AUTOSAR XML (schema 4-2-2)
package /STELLANTIS/EPT/ASWCs
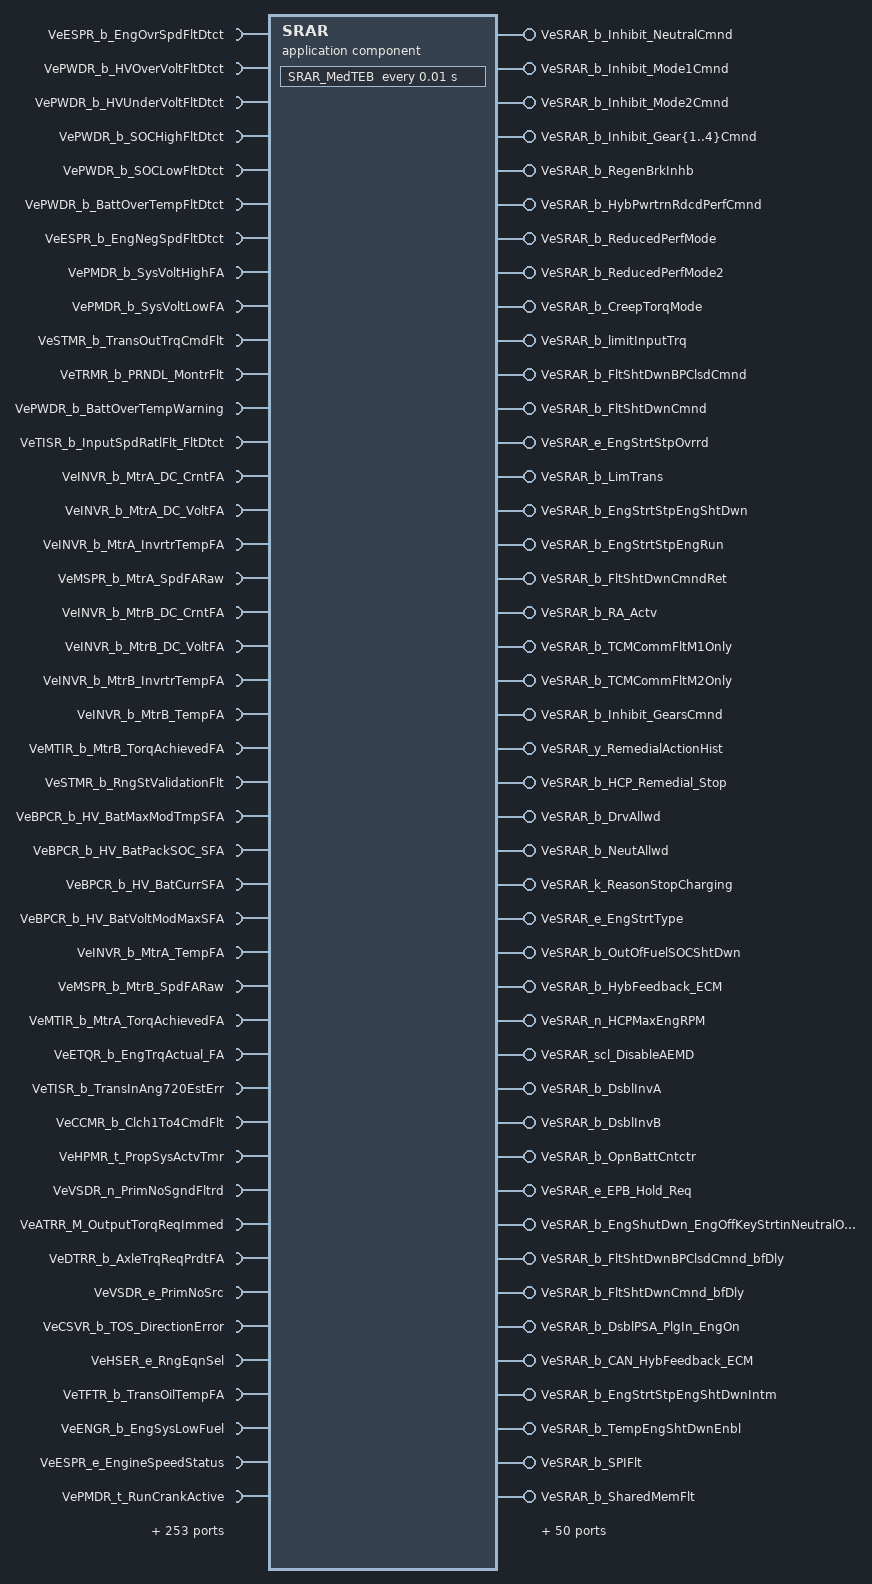
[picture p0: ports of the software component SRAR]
  application sw component type SRAR
    296 x require port:
      VeESPR_b_EngOvrSpdFltDtct: nonqueued-receiver-com-spec{data-element=Value, init-value=0}, required-interface=VeESPR_b_EngOvrSpdFltDtct
      VePWDR_b_HVOverVoltFltDtct: nonqueued-receiver-com-spec{data-element=Value, init-value=0}, required-interface=VePWDR_b_HVOverVoltFltDtct
      VePWDR_b_HVUnderVoltFltDtct: nonqueued-receiver-com-spec{data-element=Value, init-value=0}, required-interface=VePWDR_b_HVUnderVoltFltDtct
      VePWDR_b_SOCHighFltDtct: nonqueued-receiver-com-spec{data-element=Value, init-value=0}, required-interface=VePWDR_b_SOCHighFltDtct
      VePWDR_b_SOCLowFltDtct: nonqueued-receiver-com-spec{data-element=Value, init-value=0}, required-interface=VePWDR_b_SOCLowFltDtct
      VePWDR_b_BattOverTempFltDtct: nonqueued-receiver-com-spec{data-element=Value, init-value=0}, required-interface=VePWDR_b_BattOverTempFltDtct
      VeESPR_b_EngNegSpdFltDtct: nonqueued-receiver-com-spec{data-element=Value, init-value=0}, required-interface=VeESPR_b_EngNegSpdFltDtct
      VePMDR_b_SysVoltHighFA: nonqueued-receiver-com-spec{data-element=Value, init-value=0}, required-interface=VePMDR_b_SysVoltHighFA
      VePMDR_b_SysVoltLowFA: nonqueued-receiver-com-spec{data-element=Value, init-value=0}, required-interface=VePMDR_b_SysVoltLowFA
      VeSTMR_b_TransOutTrqCmdFlt: nonqueued-receiver-com-spec{data-element=Value, init-value=0}, required-interface=VeSTMR_b_TransOutTrqCmdFlt
      VeTRMR_b_PRNDL_MontrFlt: nonqueued-receiver-com-spec{data-element=Value, init-value=0}, required-interface=VeTRMR_b_PRNDL_MontrFlt
      VePWDR_b_BattOverTempWarning: nonqueued-receiver-com-spec{data-element=Value, init-value=0}, required-interface=VePWDR_b_BattOverTempWarning
      VeTISR_b_InputSpdRatlFlt_FltDtct: nonqueued-receiver-com-spec{data-element=Value, init-value=0}, required-interface=VeTISR_b_InputSpdRatlFlt_FltDtct
      VeINVR_b_MtrA_DC_CrntFA: nonqueued-receiver-com-spec{data-element=Value, init-value=0}, required-interface=VeINVR_b_MtrA_DC_CrntFA
      VeINVR_b_MtrA_DC_VoltFA: nonqueued-receiver-com-spec{data-element=Value, init-value=0}, required-interface=VeINVR_b_MtrA_DC_VoltFA
      VeINVR_b_MtrA_InvrtrTempFA: nonqueued-receiver-com-spec{data-element=Value, init-value=0}, required-interface=VeINVR_b_MtrA_InvrtrTempFA
      VeMSPR_b_MtrA_SpdFARaw: nonqueued-receiver-com-spec{data-element=Value, init-value=0}, required-interface=VeMSPR_b_MtrA_SpdFARaw
      VeINVR_b_MtrB_DC_CrntFA: nonqueued-receiver-com-spec{data-element=Value, init-value=0}, required-interface=VeINVR_b_MtrB_DC_CrntFA
      VeINVR_b_MtrB_DC_VoltFA: nonqueued-receiver-com-spec{data-element=Value, init-value=0}, required-interface=VeINVR_b_MtrB_DC_VoltFA
      VeINVR_b_MtrB_InvrtrTempFA: nonqueued-receiver-com-spec{data-element=Value, init-value=0}, required-interface=VeINVR_b_MtrB_InvrtrTempFA
      VeINVR_b_MtrB_TempFA: nonqueued-receiver-com-spec{data-element=Value, init-value=0}, required-interface=VeINVR_b_MtrB_TempFA
      VeMTIR_b_MtrB_TorqAchievedFA: nonqueued-receiver-com-spec{data-element=Value, init-value=0}, required-interface=VeMTIR_b_MtrB_TorqAchievedFA
      VeSTMR_b_RngStValidationFlt: nonqueued-receiver-com-spec{data-element=Value, init-value=0}, required-interface=VeSTMR_b_RngStValidationFlt
      VeBPCR_b_HV_BatMaxModTmpSFA: nonqueued-receiver-com-spec{data-element=Value, init-value=0}, required-interface=VeBPCR_b_HV_BatMaxModTmpSFA
      VeBPCR_b_HV_BatPackSOC_SFA: nonqueued-receiver-com-spec{data-element=Value, init-value=0}, required-interface=VeBPCR_b_HV_BatPackSOC_SFA
      VeBPCR_b_HV_BatCurrSFA: nonqueued-receiver-com-spec{data-element=Value, init-value=0}, required-interface=VeBPCR_b_HV_BatCurrSFA
      VeBPCR_b_HV_BatVoltModMaxSFA: nonqueued-receiver-com-spec{data-element=Value, init-value=0}, required-interface=VeBPCR_b_HV_BatVoltModMaxSFA
      VeINVR_b_MtrA_TempFA: nonqueued-receiver-com-spec{data-element=Value, init-value=0}, required-interface=VeINVR_b_MtrA_TempFA
      VeMSPR_b_MtrB_SpdFARaw: nonqueued-receiver-com-spec{data-element=Value, init-value=0}, required-interface=VeMSPR_b_MtrB_SpdFARaw
      VeMTIR_b_MtrA_TorqAchievedFA: nonqueued-receiver-com-spec{data-element=Value, init-value=0}, required-interface=VeMTIR_b_MtrA_TorqAchievedFA
      VeETQR_b_EngTrqActual_FA: nonqueued-receiver-com-spec{data-element=Value, init-value=0}, required-interface=VeETQR_b_EngTrqActual_FA
      VeTISR_b_TransInAng720EstErr: nonqueued-receiver-com-spec{data-element=Value, init-value=0}, required-interface=VeTISR_b_TransInAng720EstErr
      VeCCMR_b_Clch1To4CmdFlt: nonqueued-receiver-com-spec{data-element=Value, init-value=0}, required-interface=VeCCMR_b_Clch1To4CmdFlt
      VeHPMR_t_PropSysActvTmr: nonqueued-receiver-com-spec{data-element=Value, init-value=0}, required-interface=VeHPMR_t_PropSysActvTmr
      VeVSDR_n_PrimNoSgndFltrd: nonqueued-receiver-com-spec{data-element=Value, init-value=0}, required-interface=VeVSDR_n_PrimNoSgndFltrd
      VeATRR_M_OutputTorqReqImmed: nonqueued-receiver-com-spec{data-element=Value, init-value=0}, required-interface=VeATRR_M_OutputTorqReqImmed
      VeDTRR_b_AxleTrqReqPrdtFA: nonqueued-receiver-com-spec{data-element=Value, init-value=0}, required-interface=VeDTRR_b_AxleTrqReqPrdtFA
      VeVSDR_e_PrimNoSrc: nonqueued-receiver-com-spec{data-element=Value, init-value=CeVSDR_e_PrimNoSrcNotAvail}, required-interface=VeVSDR_e_PrimNoSrc
      VeCSVR_b_TOS_DirectionError: nonqueued-receiver-com-spec{data-element=Value, init-value=0}, required-interface=VeCSVR_b_TOS_DirectionError
      VeHSER_e_RngEqnSel: nonqueued-receiver-com-spec{data-element=Value, init-value=CeHSER_e_UseNeutralEqn}, required-interface=VeHSER_e_RngEqnSel
      VeTFTR_b_TransOilTempFA: nonqueued-receiver-com-spec{data-element=Value, init-value=0}, required-interface=VeTFTR_b_TransOilTempFA
      VeENGR_b_EngSysLowFuel: nonqueued-receiver-com-spec{data-element=Value, init-value=0}, required-interface=VeENGR_b_EngSysLowFuel
      VeESPR_e_EngineSpeedStatus: nonqueued-receiver-com-spec{data-element=Value, init-value=CeESPR_e_EngSpdNormal}, required-interface=VeESPR_e_EngineSpeedStatus
      VePMDR_t_RunCrankActive: nonqueued-receiver-com-spec{data-element=Value, init-value=0}, required-interface=VePMDR_t_RunCrankActive
      VeTIDR_b_EngTrqHVBattLoFA: nonqueued-receiver-com-spec{data-element=Value, init-value=0}, required-interface=VeTIDR_b_EngTrqHVBattLoFA
      VeTIDR_b_EngTrqHVBattHiFA: nonqueued-receiver-com-spec{data-element=Value, init-value=0}, required-interface=VeTIDR_b_EngTrqHVBattHiFA
      VeCSLR_n_Clch1_RawSlipSpeed: nonqueued-receiver-com-spec{data-element=Value, init-value=0}, required-interface=VeCSLR_n_Clch1_RawSlipSpeed
      VeCSLR_n_Clch2_RawSlipSpeed: nonqueued-receiver-com-spec{data-element=Value, init-value=0}, required-interface=VeCSLR_n_Clch2_RawSlipSpeed
      VeDFIR_b_PostCodeClrDiagDsbl: nonqueued-receiver-com-spec{data-element=Value, init-value=0}, required-interface=VeDFIR_b_PostCodeClrDiagDsbl
      VePMDR_e_PMM_PowerMode: nonqueued-receiver-com-spec{data-element=Value, init-value=CePMDR_e_PowerMode_Off}, required-interface=VePMDR_e_PMM_PowerMode
      VeSTRR_b_ImmedStop: nonqueued-receiver-com-spec{data-element=Value, init-value=0}, required-interface=VeSTRR_b_ImmedStop
      VeHPMR_b_MtrSystemActive: nonqueued-receiver-com-spec{data-element=Value, init-value=0}, required-interface=VeHPMR_b_MtrSystemActive
      VeTISR_n_InputSpeed: nonqueued-receiver-com-spec{data-element=Value, init-value=0}, required-interface=VeTISR_n_InputSpeed
      VeESSR_e_EngStrtStpMd: nonqueued-receiver-com-spec{data-element=Value, init-value=CeESSR_e_Stop}, required-interface=VeESSR_e_EngStrtStpMd
      VeBPCR_Pct_HV_BatPackSOC_Arb: nonqueued-receiver-com-spec{data-element=Value, init-value=0}, required-interface=VeBPCR_Pct_HV_BatPackSOC_Arb
      VeHPMR_b_PropSysActv: nonqueued-receiver-com-spec{data-element=Value, init-value=0}, required-interface=VeHPMR_b_PropSysActv
      VeENGR_b_EngOffRecom: nonqueued-receiver-com-spec{data-element=Value, init-value=0}, required-interface=VeENGR_b_EngOffRecom
      VeENGR_b_ZylAbs: nonqueued-receiver-com-spec{data-element=Value, init-value=0}, required-interface=VeENGR_b_ZylAbs
      VeETQR_M_EngTrqActual: nonqueued-receiver-com-spec{data-element=Value, init-value=0}, required-interface=VeETQR_M_EngTrqActual
      VeOHSR_e_RngDsrd: nonqueued-receiver-com-spec{data-element=Value, init-value=CeOHSR_e_RngSel_N}, required-interface=VeOHSR_e_RngDsrd
      VeHSER_e_RngSt: nonqueued-receiver-com-spec{data-element=Value, init-value=CeHSER_e_Init}, required-interface=VeHSER_e_RngSt
      VeTFTR_T_TransOilTemp: nonqueued-receiver-com-spec{data-element=Value, init-value=0}, required-interface=VeTFTR_T_TransOilTemp
      VeHCCR_e_SCA1_St: nonqueued-receiver-com-spec{data-element=Value, init-value=CeHCCR_e_SCA_Filling_Md}, required-interface=VeHCCR_e_SCA1_St
      VeHCCR_e_SCA2_St: nonqueued-receiver-com-spec{data-element=Value, init-value=CeHCCR_e_SCA_Filling_Md}, required-interface=VeHCCR_e_SCA2_St
      VeTHMR_e_ThrmSysShtDwnFlt: nonqueued-receiver-com-spec{data-element=Value, init-value=CeSRAR_e_NoFlt}, required-interface=VeTHMR_e_ThrmSysShtDwnFlt
      VeOBCR_e_ChrgSysShtDwnFlt: nonqueued-receiver-com-spec{data-element=Value, init-value=CeSRAR_e_NoFlt}, required-interface=VeOBCR_e_ChrgSysShtDwnFlt
      VeBTQR_b_RegenBrkAxleTrqReqFA: nonqueued-receiver-com-spec{data-element=Value, init-value=0}, required-interface=VeBTQR_b_RegenBrkAxleTrqReqFA
      VeBTQR_M_RegenBrkAxleTrqReq: nonqueued-receiver-com-spec{data-element=Value, init-value=0}, required-interface=VeBTQR_M_RegenBrkAxleTrqReq
      VeGENR_b_LowVoltSysFld: nonqueued-receiver-com-spec{data-element=Value, init-value=0}, required-interface=VeGENR_b_LowVoltSysFld
      VeGENR_U_IBS_BattVoltOut: nonqueued-receiver-com-spec{data-element=Value, init-value=0}, required-interface=VeGENR_U_IBS_BattVoltOut
      VeCSVR_v_VehSpd: nonqueued-receiver-com-spec{data-element=Value, init-value=0}, required-interface=VeCSVR_v_VehSpd
      VeESSR_b_AStrtFailed: nonqueued-receiver-com-spec{data-element=Value, init-value=0}, required-interface=VeESSR_b_AStrtFailed
      VeSTRR_e_HybStrtrSt: nonqueued-receiver-com-spec{data-element=Value, init-value=CeSTRR_e_KeyOffSt}, required-interface=VeSTRR_e_HybStrtrSt
      VeTRGR_e_VldtdTransRngSt: nonqueued-receiver-com-spec{data-element=Value, init-value=CeTRGR_e_NoSelectionAvailable}, required-interface=VeTRGR_e_VldtdTransRngSt
      VeBPCR_b_PwrLimON: nonqueued-receiver-com-spec{data-element=Value, init-value=0}, required-interface=VeBPCR_b_PwrLimON
      VeTISR_b_InputSpeedFA: nonqueued-receiver-com-spec{data-element=Value, init-value=0}, required-interface=VeTISR_b_InputSpeedFA
      VeESSR_e_EngStartStopSt: nonqueued-receiver-com-spec{data-element=Value, init-value=CeESSR_e_EngOff}, required-interface=VeESSR_e_EngStartStopSt
      VeOBCR_e_ChargingLevel: nonqueued-receiver-com-spec{data-element=Value, init-value=CeOBCR_e_ChargingLvlDefault}, required-interface=VeOBCR_e_ChargingLevel
      VePLTR_b_RmtVehStartReq: nonqueued-receiver-com-spec{data-element=Value, init-value=0}, required-interface=VePLTR_b_RmtVehStartReq
      VeSSDR_b_DrvAllwd: nonqueued-receiver-com-spec{data-element=Value, init-value=0}, required-interface=VeSSDR_b_DrvAllwd
      VeGSMR_b_PpawlInsrtMntrFailed: nonqueued-receiver-com-spec{data-element=Value, init-value=0}, required-interface=VeGSMR_b_PpawlInsrtMntrFailed
      VeTAPR_b_TransAuxPump_NotFlty: nonqueued-receiver-com-spec{data-element=Value, init-value=0}, required-interface=VeTAPR_b_TransAuxPump_NotFlty
      VeHCCR_V_UpperSump_Vol: nonqueued-receiver-com-spec{data-element=Value, init-value=0}, required-interface=VeHCCR_V_UpperSump_Vol
      VeCSDR_b_Clch1_Avail: nonqueued-receiver-com-spec{data-element=Value, init-value=0}, required-interface=VeCSDR_b_Clch1_Avail
      VeCSDR_b_Clch2_Avail: nonqueued-receiver-com-spec{data-element=Value, init-value=0}, required-interface=VeCSDR_b_Clch2_Avail
      VeTINR_b_Inhibit_Mode1: nonqueued-receiver-com-spec{data-element=Value, init-value=0}, required-interface=VeTINR_b_Inhibit_Mode1
      VeTINR_b_Inhibit_Mode2: nonqueued-receiver-com-spec{data-element=Value, init-value=0}, required-interface=VeTINR_b_Inhibit_Mode2
      VeTINR_b_Inhibit_Gear{1..4}: nonqueued-receiver-com-spec{data-element=Value, init-value=0}, required-interface=VeTINR_b_Inhibit_Gear{1..4}
      VeTINR_b_Inhibit_Neutral: nonqueued-receiver-com-spec{data-element=Value, init-value=0}, required-interface=VeTINR_b_Inhibit_Neutral
      VePWDR_e_HVOverVoltFailure: nonqueued-receiver-com-spec{data-element=Value, init-value=CeHVTR_e_HVOverVoltPass}, required-interface=VePWDR_e_HVOverVoltFailure
      VeMMMR_b_MtrMdVldtnFlt: nonqueued-receiver-com-spec{data-element=Value, init-value=0}, required-interface=VeMMMR_b_MtrMdVldtnFlt
      VeTITR_M_SnsdEng_Flt: nonqueued-receiver-com-spec{data-element=Value, init-value=0}, required-interface=VeTITR_M_SnsdEng_Flt
      VeTRGR_b_DisableDrvAllwd: nonqueued-receiver-com-spec{data-element=Value, init-value=0}, required-interface=VeTRGR_b_DisableDrvAllwd
      VeHPMR_e_PropSysMode: nonqueued-receiver-com-spec{data-element=Value, init-value=CeHPMR_e_Disabled}, required-interface=VeHPMR_e_PropSysMode
      VeTRGR_e_EPB_Hold_Req: nonqueued-receiver-com-spec{data-element=Value, init-value=CeTRGR_e_EPBReq_NA}, required-interface=VeTRGR_e_EPB_Hold_Req
      VeTINR_d_TCMFailures: nonqueued-receiver-com-spec{data-element=Value, init-value=0}, required-interface=VeTINR_d_TCMFailures
      VeTHMR_e_PPCTIS_OT: nonqueued-receiver-com-spec{data-element=Value, init-value=CeTHMR_e_EmergencyLevel4}, required-interface=VeTHMR_e_PPCTIS_OT
      VePMIR_e_LTPsvPumpDryRun: nonqueued-receiver-com-spec{data-element=Value, init-value=CePMPR_e_FTSNA_False}, required-interface=VePMIR_e_LTPsvPumpDryRun
      VeCPDR_b_LTPP_FunPer_FltDtct: nonqueued-receiver-com-spec{data-element=Value, init-value=0}, required-interface=VeCPDR_b_LTPP_FunPer_FltDtct
      VeESSR_g_StrtStpFailPhase: nonqueued-receiver-com-spec{data-element=Value, init-value=0}, required-interface=VeESSR_g_StrtStpFailPhase
      VeINVR_e_MtrA_InvrtrSt: nonqueued-receiver-com-spec{data-element=Value, init-value=CeINVR_e_NormalPowerStageOff}, required-interface=VeINVR_e_MtrA_InvrtrSt
      VeTTIR_b_TransTrqReqFst_Pass: nonqueued-receiver-com-spec{data-element=Value, init-value=0}, required-interface=VeTTIR_b_TransTrqReqFst_Pass
      VeENGR_b_ECM_Feedback_HCP: nonqueued-receiver-com-spec{data-element=Value, init-value=0}, required-interface=VeENGR_b_ECM_Feedback_HCP
      VeESSR_b_AStrtReattmptAllowed: nonqueued-receiver-com-spec{data-element=Value, init-value=0}, required-interface=VeESSR_b_AStrtReattmptAllowed
      VePLTR_b_InFieldMode: nonqueued-receiver-com-spec{data-element=Value, init-value=0}, required-interface=VePLTR_b_InFieldMode
      VePMDR_e_KeyStatus: nonqueued-receiver-com-spec{data-element=Value, init-value=CePMDR_e_KeySt_Off}, required-interface=VePMDR_e_KeyStatus
      VeOBCR_e_ChargingSystemSts: nonqueued-receiver-com-spec{data-element=Value, init-value=CeOBCR_e_NotCharging}, required-interface=VeOBCR_e_ChargingSystemSts
      VeTMIR_T_PsvPmpClnt_TmpIn: nonqueued-receiver-com-spec{data-element=Value, init-value=0}, required-interface=VeTMIR_T_PsvPmpClnt_TmpIn
      VeINVR_T_MtrB_InvrtrTemp: nonqueued-receiver-com-spec{data-element=Value, init-value=0}, required-interface=VeINVR_T_MtrB_InvrtrTemp
      VeINVR_T_MtrA_InvrtrTemp: nonqueued-receiver-com-spec{data-element=Value, init-value=0}, required-interface=VeINVR_T_MtrA_InvrtrTemp
      VeINVR_T_MtrB_Temp: nonqueued-receiver-com-spec{data-element=Value, init-value=0}, required-interface=VeINVR_T_MtrB_Temp
      VeINVR_T_MtrA_Temp: nonqueued-receiver-com-spec{data-element=Value, init-value=0}, required-interface=VeINVR_T_MtrA_Temp
      VeBPCR_b_HV_BatCntctrOpenPending: nonqueued-receiver-com-spec{data-element=Value, init-value=0}, required-interface=VeBPCR_b_HV_BatCntctrOpenPending
      VeINVR_b_MtrAFlt_HV_CntctrOpnRq: nonqueued-receiver-com-spec{data-element=Value, init-value=0}, required-interface=VeINVR_b_MtrAFlt_HV_CntctrOpnRq
      VeHSCR_n_Max_MtrA_Spd: nonqueued-receiver-com-spec{data-element=Value, init-value=0}, required-interface=VeHSCR_n_Max_MtrA_Spd
      VeINVR_b_MtrBFlt_HV_CntctrOpnRq: nonqueued-receiver-com-spec{data-element=Value, init-value=0}, required-interface=VeINVR_b_MtrBFlt_HV_CntctrOpnRq
      VeINVR_e_MtrB_InvrtrSt: nonqueued-receiver-com-spec{data-element=Value, init-value=CeINVR_e_NormalPowerStageOff}, required-interface=VeINVR_e_MtrB_InvrtrSt
      VeHSCR_n_Max_MtrB_Spd: nonqueued-receiver-com-spec{data-element=Value, init-value=0}, required-interface=VeHSCR_n_Max_MtrB_Spd
      VeTRNR_e_ActualGear: nonqueued-receiver-com-spec{data-element=Value, init-value=CeTRNR_e_Neutral}, required-interface=VeTRNR_e_ActualGear
      VeTRNR_e_TargetGear: nonqueued-receiver-com-spec{data-element=Value, init-value=CeTRNR_e_Neutral}, required-interface=VeTRNR_e_TargetGear
      VeTRNR_e_C1Stat: nonqueued-receiver-com-spec{data-element=Value, init-value=CeHCCR_e_ClInvalid}, required-interface=VeTRNR_e_C1Stat
      VeOSMR_n_TransMinEngSpd: nonqueued-receiver-com-spec{data-element=Value, init-value=0}, required-interface=VeOSMR_n_TransMinEngSpd
      VeENGR_e_ECMReqRemStop: nonqueued-receiver-com-spec{data-element=Value, init-value=CeENGR_e_Default}, required-interface=VeENGR_e_ECMReqRemStop
      VeBPCR_b_HV_BatCntctrOpenReq: nonqueued-receiver-com-spec{data-element=Value, init-value=0}, required-interface=VeBPCR_b_HV_BatCntctrOpenReq
      VeENGR_b_LV12PwrFreeRq: nonqueued-receiver-com-spec{data-element=Value, init-value=0}, required-interface=VeENGR_b_LV12PwrFreeRq
      VeENGR_b_EngTrq_Enbl_Rq_TCM: nonqueued-receiver-com-spec{data-element=Value, init-value=0}, required-interface=VeENGR_b_EngTrq_Enbl_Rq_TCM
      VeENGR_i_ECM_LHOM_Trans: nonqueued-receiver-com-spec{data-element=Value, init-value=0}, required-interface=VeENGR_i_ECM_LHOM_Trans
      VeCSLR_b_NC1_FA: nonqueued-receiver-com-spec{data-element=Value, init-value=0}, required-interface=VeCSLR_b_NC1_FA
      VeTINR_d_TCMLimphomeFaults: nonqueued-receiver-com-spec{data-element=Value, init-value=0}, required-interface=VeTINR_d_TCMLimphomeFaults
      VeTHMR_b_ThermalHybAltMode_Rq: nonqueued-receiver-com-spec{data-element=Value, init-value=0}, required-interface=VeTHMR_b_ThermalHybAltMode_Rq
      VeENGR_e_ComFailECM_C1CAN: nonqueued-receiver-com-spec{data-element=Value, init-value=CeENGR_e_NoFaultECM_C1}, required-interface=VeENGR_e_ComFailECM_C1CAN
      VeENGR_e_ComFailECM_ePtCAN: nonqueued-receiver-com-spec{data-element=Value, init-value=CeENGR_e_NoFaultECM_ePT}, required-interface=VeENGR_e_ComFailECM_ePtCAN
      VeTINR_e_ComFailTCM_C1CAN: nonqueued-receiver-com-spec{data-element=Value, init-value=CeTINR_e_NoFaultTCM_C1}, required-interface=VeTINR_e_ComFailTCM_C1CAN
      VeTINR_e_ComFailTCM_ePtCAN: nonqueued-receiver-com-spec{data-element=Value, init-value=CeTINR_e_NoFaultTCM_ePT}, required-interface=VeTINR_e_ComFailTCM_ePtCAN
      VeBRKR_e_ComFailBSM_C1CAN: nonqueued-receiver-com-spec{data-element=Value, init-value=CeBRKR_e_NoFaultBSM_C1}, required-interface=VeBRKR_e_ComFailBSM_C1CAN
      VeBRKR_e_ComFailBSM_C2CAN: nonqueued-receiver-com-spec{data-element=Value, init-value=CeBRKR_e_NoFaultBSM_C2}, required-interface=VeBRKR_e_ComFailBSM_C2CAN
      VeHTRR_b_Htr3Cntctr_StckClsdOvrTmp_Flg: nonqueued-receiver-com-spec{data-element=Value, init-value=0}, required-interface=VeHTRR_b_Htr3Cntctr_StckClsdOvrTmp_Flg
      VeIDCR_e_APM_FailureType: nonqueued-receiver-com-spec{data-element=Value, init-value=CeGENR_e_FailureType_NoFailure}, required-interface=VeIDCR_e_APM_FailureType
      VeBRKR_b_ABSActive: nonqueued-receiver-com-spec{data-element=Value, init-value=0}, required-interface=VeBRKR_b_ABSActive
      VeBRKR_b_ImpndSkid: nonqueued-receiver-com-spec{data-element=Value, init-value=0}, required-interface=VeBRKR_b_ImpndSkid
      VePMDR_b_SysVoltLowFA_BF1: nonqueued-receiver-com-spec{data-element=Value, init-value=0}, required-interface=VePMDR_b_SysVoltLowFA_BF1
      VePMDR_b_SysVoltLowFA_BF2: nonqueued-receiver-com-spec{data-element=Value, init-value=0}, required-interface=VePMDR_b_SysVoltLowFA_BF2
      VePMDR_b_SysVoltLowFA_HB: nonqueued-receiver-com-spec{data-element=Value, init-value=0}, required-interface=VePMDR_b_SysVoltLowFA_HB
      VeDMIR_e_DriveStyleSts: nonqueued-receiver-com-spec{data-element=Value, init-value=CeDMIR_e_Normal}, required-interface=VeDMIR_e_DriveStyleSts
      VeDTRR_b_OPDInhibit_HMI: nonqueued-receiver-com-spec{data-element=Value, init-value=0}, required-interface=VeDTRR_b_OPDInhibit_HMI
      VeAPSR_e_Lv1PVMode: nonqueued-receiver-com-spec{data-element=Value, init-value=CeAPSR_e_LV1PVMode_NotValid}, required-interface=VeAPSR_e_Lv1PVMode
      VeHSER_b_GRMActive: nonqueued-receiver-com-spec{data-element=Value, init-value=0}, required-interface=VeHSER_b_GRMActive
      VeSTRR_b_BumpStrtEngOn: nonqueued-receiver-com-spec{data-element=Value, init-value=0}, required-interface=VeSTRR_b_BumpStrtEngOn
      VeTINR_e_TransLimpRequest: nonqueued-receiver-com-spec{data-element=Value, init-value=CeTINR_e_LimpInactive}, required-interface=VeTINR_e_TransLimpRequest
      VeBPCR_b_ThrmlRnawyFlg: nonqueued-receiver-com-spec{data-element=Value, init-value=0}, required-interface=VeBPCR_b_ThrmlRnawyFlg
      VeSTRR_b_BumpStrtInhbt: nonqueued-receiver-com-spec{data-element=Value, init-value=0}, required-interface=VeSTRR_b_BumpStrtInhbt
      VeTRNR_e_C2Stat: nonqueued-receiver-com-spec{data-element=Value, init-value=CeHCCR_e_ClInvalid}, required-interface=VeTRNR_e_C2Stat
      VeDTRR_b_DrvrIntndedAxleTrqRawFA: nonqueued-receiver-com-spec{data-element=Value, init-value=0}, required-interface=VeDTRR_b_DrvrIntndedAxleTrqRawFA
      VeENGR_b_EngineStallDetected: nonqueued-receiver-com-spec{data-element=Value, init-value=0}, required-interface=VeENGR_b_EngineStallDetected
      VeCPDR_b_LTCL_FunPer_FltDtct: nonqueued-receiver-com-spec{data-element=Value, init-value=0}, required-interface=VeCPDR_b_LTCL_FunPer_FltDtct
      VeCPDR_b_LTCL_DryRun_FltDtct: nonqueued-receiver-com-spec{data-element=Value, init-value=0}, required-interface=VeCPDR_b_LTCL_DryRun_FltDtct
      VeBRKR_b_AeCoastReady: nonqueued-receiver-com-spec{data-element=Value, init-value=0}, required-interface=VeBRKR_b_AeCoastReady
      VeINVR_b_P1f_Dgrd_AltMd: nonqueued-receiver-com-spec{data-element=Value, init-value=0}, required-interface=VeINVR_b_P1f_Dgrd_AltMd
      VeTRNR_e_TCMActualEvenGear: nonqueued-receiver-com-spec{data-element=Value, init-value=CeTRNR_e_Neutral}, required-interface=VeTRNR_e_TCMActualEvenGear
      VeTINR_e_Synchro2Sts: nonqueued-receiver-com-spec{data-element=Value, init-value=CeHCCR_e_ClInvalid}, required-interface=VeTINR_e_Synchro2Sts
      VeTINR_e_Synchro1Sts: nonqueued-receiver-com-spec{data-element=Value, init-value=CeHCCR_e_ClInvalid}, required-interface=VeTINR_e_Synchro1Sts
      VeIMPR_b_HighVoltageRapidShtdwnCmnd: nonqueued-receiver-com-spec{data-element=Value, init-value=0}, required-interface=VeIMPR_b_HighVoltageRapidShtdwnCmnd
      VeBPCR_b_HVBatCntrWeld_ImpdOpn: nonqueued-receiver-com-spec{data-element=Value, init-value=0}, required-interface=VeBPCR_b_HVBatCntrWeld_ImpdOpn
      VeCSVR_b_CanSigVehSpd_FA: nonqueued-receiver-com-spec{data-element=Value, init-value=0}, required-interface=VeCSVR_b_CanSigVehSpd_FA
      VeCSVR_b_VehSpdVSOSigFailSts: nonqueued-receiver-com-spec{data-element=Value, init-value=0}, required-interface=VeCSVR_b_VehSpdVSOSigFailSts
      VePMDR_b_SysVoltLowFA_BF3: nonqueued-receiver-com-spec{data-element=Value, init-value=0}, required-interface=VePMDR_b_SysVoltLowFA_BF3
      VeMSPR_n_MtrB_Spd: nonqueued-receiver-com-spec{data-element=Value, init-value=0}, required-interface=VeMSPR_n_MtrB_Spd
      VeINVR_e_MtrC_InvrtrSt: nonqueued-receiver-com-spec{data-element=Value, init-value=CeINVR_e_NormalPowerStageOff}, required-interface=VeINVR_e_MtrC_InvrtrSt
      VeINVR_b_MtrCFlt_HV_CntctrOpnRq: nonqueued-receiver-com-spec{data-element=Value, init-value=0}, required-interface=VeINVR_b_MtrCFlt_HV_CntctrOpnRq
      VeINVR_e_MCPA_CommFail: nonqueued-receiver-com-spec{data-element=Value, init-value=CeSRAR_e_CommFail_NoFault}, required-interface=VeINVR_e_MCPA_CommFail
      VeINVR_e_MCPB_CommFail: nonqueued-receiver-com-spec{data-element=Value, init-value=CeSRAR_e_CommFail_NoFault}, required-interface=VeINVR_e_MCPB_CommFail
      VeINVR_b_MCPA_CommFailFA: nonqueued-receiver-com-spec{data-element=Value, init-value=0}, required-interface=VeINVR_b_MCPA_CommFailFA
      VeINVR_b_MCPB_CommFailFA: nonqueued-receiver-com-spec{data-element=Value, init-value=0}, required-interface=VeINVR_b_MCPB_CommFailFA
      VeBPCR_e_BPCM_CommFail: nonqueued-receiver-com-spec{data-element=Value, init-value=CeSRAR_e_CommFail_NoFault}, required-interface=VeBPCR_e_BPCM_CommFail
      VeBPCR_b_BPCM_CommFailFA: nonqueued-receiver-com-spec{data-element=Value, init-value=0}, required-interface=VeBPCR_b_BPCM_CommFailFA
      VeINVR_b_MtrBFlt_HV_CntctrOpnRq_FA: nonqueued-receiver-com-spec{data-element=Value, init-value=0}, required-interface=VeINVR_b_MtrBFlt_HV_CntctrOpnRq_FA
      VeBPCR_b_HVBatCntctrWeld_Qualifier: nonqueued-receiver-com-spec{data-element=Value, init-value=0}, required-interface=VeBPCR_b_HVBatCntctrWeld_Qualifier
      VeAPSR_b_AccelPedalEffPositionFA: nonqueued-receiver-com-spec{data-element=Value, init-value=0}, required-interface=VeAPSR_b_AccelPedalEffPositionFA
      VeADIR_b_LftWEDClosingFail: nonqueued-receiver-com-spec{data-element=Value, init-value=0}, required-interface=VeADIR_b_LftWEDClosingFail
      VeADIR_b_LftWEDOpeningFail: nonqueued-receiver-com-spec{data-element=Value, init-value=0}, required-interface=VeADIR_b_LftWEDOpeningFail
      VeADIR_b_RtWEDClosingFail: nonqueued-receiver-com-spec{data-element=Value, init-value=0}, required-interface=VeADIR_b_RtWEDClosingFail
      VeADIR_b_RtWEDOpeningFail: nonqueued-receiver-com-spec{data-element=Value, init-value=0}, required-interface=VeADIR_b_RtWEDOpeningFail
      VeDMAB_y_StatusByte_CM_AD_Perf: nonqueued-receiver-com-spec{data-element=Value, init-value=0}, required-interface=VeDMAB_y_StatusByte_CM_AD_Perf
      VeDMAB_y_StatusByte_CM_Chksum_Err: nonqueued-receiver-com-spec{data-element=Value, init-value=0}, required-interface=VeDMAB_y_StatusByte_CM_Chksum_Err
      VeDMAB_y_StatusByte_CM_LongTermMemReset: nonqueued-receiver-com-spec{data-element=Value, init-value=0}, required-interface=VeDMAB_y_StatusByte_CM_LongTermMemReset
      VeDMAB_y_StatusByte_CM_MainProc: nonqueued-receiver-com-spec{data-element=Value, init-value=0}, required-interface=VeDMAB_y_StatusByte_CM_MainProc
      VeDMAB_y_StatusByte_CM_OPDActivePerf: nonqueued-receiver-com-spec{data-element=Value, init-value=0}, required-interface=VeDMAB_y_StatusByte_CM_OPDActivePerf
      VeDMAB_y_StatusByte_CM_PLD: nonqueued-receiver-com-spec{data-element=Value, init-value=0}, required-interface=VeDMAB_y_StatusByte_CM_PLD
      VeDMAB_y_StatusByte_CM_ProcessorPerf: nonqueued-receiver-com-spec{data-element=Value, init-value=0}, required-interface=VeDMAB_y_StatusByte_CM_ProcessorPerf
      VeDMAB_y_StatusByte_CM_RAM_Err: nonqueued-receiver-com-spec{data-element=Value, init-value=0}, required-interface=VeDMAB_y_StatusByte_CM_RAM_Err
      VeDMAB_y_StatusByte_CM_ROM_Err: nonqueued-receiver-com-spec{data-element=Value, init-value=0}, required-interface=VeDMAB_y_StatusByte_CM_ROM_Err
      VeDMAB_y_StatusByte_CM_RedundMemPerf: nonqueued-receiver-com-spec{data-element=Value, init-value=0}, required-interface=VeDMAB_y_StatusByte_CM_RedundMemPerf
      VeDMAB_y_StatusByte_CommBusOff: nonqueued-receiver-com-spec{data-element=Value, init-value=0}, required-interface=VeDMAB_y_StatusByte_CommBusOff
      VeDMAB_y_StatusByte_FD_CAN14_CommBusOff: nonqueued-receiver-com-spec{data-element=Value, init-value=0}, required-interface=VeDMAB_y_StatusByte_FD_CAN14_CommBusOff
      VeDMAB_y_StatusByte_FD_CAN14_CommBusPerf: nonqueued-receiver-com-spec{data-element=Value, init-value=0}, required-interface=VeDMAB_y_StatusByte_FD_CAN14_CommBusPerf
      VeDMAB_y_StatusByte_FD_CAN3_CommBusOff: nonqueued-receiver-com-spec{data-element=Value, init-value=0}, required-interface=VeDMAB_y_StatusByte_FD_CAN3_CommBusOff
      VeDMAB_y_StatusByte_FD_CAN3_CommBusPerf: nonqueued-receiver-com-spec{data-element=Value, init-value=0}, required-interface=VeDMAB_y_StatusByte_FD_CAN3_CommBusPerf
      VeDMAB_y_StatusByte_Fault: nonqueued-receiver-com-spec{data-element=Value, init-value=0}, required-interface=VeDMAB_y_StatusByte_Fault
      VeDMAB_y_StatusByte_HiSpdCANCommBusPerf: nonqueued-receiver-com-spec{data-element=Value, init-value=0}, required-interface=VeDMAB_y_StatusByte_HiSpdCANCommBusPerf
      VeDMAB_y_StatusByte_HiSpdCANCommBus: nonqueued-receiver-com-spec{data-element=Value, init-value=0}, required-interface=VeDMAB_y_StatusByte_HiSpdCANCommBus
      VeDMAB_y_StatusByte_InvData_ABSCM_A: nonqueued-receiver-com-spec{data-element=Value, init-value=0}, required-interface=VeDMAB_y_StatusByte_InvData_ABSCM_A
      VeDMAB_y_StatusByte_InvData_BCS: nonqueued-receiver-com-spec{data-element=Value, init-value=0}, required-interface=VeDMAB_y_StatusByte_InvData_BCS
      VeDMAB_y_StatusByte_InvData_HapticCM: nonqueued-receiver-com-spec{data-element=Value, init-value=0}, required-interface=VeDMAB_y_StatusByte_InvData_HapticCM
      VeDMAB_y_StatusByte_LosComWitAntBraSysABSConModB: nonqueued-receiver-com-spec{data-element=Value, init-value=0}, required-interface=VeDMAB_y_StatusByte_LosComWitAntBraSysABSConModB
      VeDMAB_y_StatusByte_LostCommABSCM_A: nonqueued-receiver-com-spec{data-element=Value, init-value=0}, required-interface=VeDMAB_y_StatusByte_LostCommABSCM_A
      VeDMAB_y_StatusByte_LostCommHapticCM: nonqueued-receiver-com-spec{data-element=Value, init-value=0}, required-interface=VeDMAB_y_StatusByte_LostCommHapticCM
      VeDMAB_y_StatusByte_LostCommIPC: nonqueued-receiver-com-spec{data-element=Value, init-value=0}, required-interface=VeDMAB_y_StatusByte_LostCommIPC
      VeDMAB_y_StatusByte_SPI_CommFlt: nonqueued-receiver-com-spec{data-element=Value, init-value=0}, required-interface=VeDMAB_y_StatusByte_SPI_CommFlt
      VeDMAB_y_StatusByte_HybSysPerf1: nonqueued-receiver-com-spec{data-element=Value, init-value=0}, required-interface=VeDMAB_y_StatusByte_HybSysPerf1
      VeDMAB_y_StatusByte_HybSysPerf2: nonqueued-receiver-com-spec{data-element=Value, init-value=0}, required-interface=VeDMAB_y_StatusByte_HybSysPerf2
      VeDMAB_y_StatusByte_HybSysPerf5: nonqueued-receiver-com-spec{data-element=Value, init-value=0}, required-interface=VeDMAB_y_StatusByte_HybSysPerf5
      VeDMAB_y_StatusByte_InvData_ECM_BusB: nonqueued-receiver-com-spec{data-element=Value, init-value=0}, required-interface=VeDMAB_y_StatusByte_InvData_ECM_BusB
      VeDMAB_y_StatusByte_InvData_ECM: nonqueued-receiver-com-spec{data-element=Value, init-value=0}, required-interface=VeDMAB_y_StatusByte_InvData_ECM
      VeDMAB_y_StatusByte_LostCommECM_A_BusB: nonqueued-receiver-com-spec{data-element=Value, init-value=0}, required-interface=VeDMAB_y_StatusByte_LostCommECM_A_BusB
      VeDMAB_y_StatusByte_LostCommECM_PCM_A: nonqueued-receiver-com-spec{data-element=Value, init-value=0}, required-interface=VeDMAB_y_StatusByte_LostCommECM_PCM_A
      VeDMAB_y_StatusByte_CommBus_B_Off: nonqueued-receiver-com-spec{data-element=Value, init-value=0}, required-interface=VeDMAB_y_StatusByte_CommBus_B_Off
      VeDMAB_y_StatusByte_FD_CAN11_CommBusOff: nonqueued-receiver-com-spec{data-element=Value, init-value=0}, required-interface=VeDMAB_y_StatusByte_FD_CAN11_CommBusOff
      VeDMAB_y_StatusByte_FD_CAN11_CommBusPerf: nonqueued-receiver-com-spec{data-element=Value, init-value=0}, required-interface=VeDMAB_y_StatusByte_FD_CAN11_CommBusPerf
      VeDMAB_y_StatusByte_FD_CAN5_CommBusOff: nonqueued-receiver-com-spec{data-element=Value, init-value=0}, required-interface=VeDMAB_y_StatusByte_FD_CAN5_CommBusOff
      VeDMAB_y_StatusByte_FD_CAN5_CommBusPerf: nonqueued-receiver-com-spec{data-element=Value, init-value=0}, required-interface=VeDMAB_y_StatusByte_FD_CAN5_CommBusPerf
      VeDMAB_y_StatusByte_HybBatPosConConCirPer: nonqueued-receiver-com-spec{data-element=Value, init-value=0}, required-interface=VeDMAB_y_StatusByte_HybBatPosConConCirPer
      VeDMAB_y_StatusByte_InvData_APM: nonqueued-receiver-com-spec{data-element=Value, init-value=0}, required-interface=VeDMAB_y_StatusByte_InvData_APM
      VeDMAB_y_StatusByte_InvData_BECM_CANC11: nonqueued-receiver-com-spec{data-element=Value, init-value=0}, required-interface=VeDMAB_y_StatusByte_InvData_BECM_CANC11
      VeDMAB_y_StatusByte_InvData_BECM: nonqueued-receiver-com-spec{data-element=Value, init-value=0}, required-interface=VeDMAB_y_StatusByte_InvData_BECM
      VeDMAB_y_StatusByte_InvData_IDCM: nonqueued-receiver-com-spec{data-element=Value, init-value=0}, required-interface=VeDMAB_y_StatusByte_InvData_IDCM
      VeDMAB_y_StatusByte_LosCommBECM_A_CANC11: nonqueued-receiver-com-spec{data-element=Value, init-value=0}, required-interface=VeDMAB_y_StatusByte_LosCommBECM_A_CANC11
      VeDMAB_y_StatusByte_LosCommBECM_A: nonqueued-receiver-com-spec{data-element=Value, init-value=0}, required-interface=VeDMAB_y_StatusByte_LosCommBECM_A
      VeDMAB_y_StatusByte_LostCommDCDC: nonqueued-receiver-com-spec{data-element=Value, init-value=0}, required-interface=VeDMAB_y_StatusByte_LostCommDCDC
      VeDMAB_y_StatusByte_LostCommIDCM: nonqueued-receiver-com-spec{data-element=Value, init-value=0}, required-interface=VeDMAB_y_StatusByte_LostCommIDCM
      VeDMAB_y_StatusByte_HybridGenPerf_Slip: nonqueued-receiver-com-spec{data-element=Value, init-value=0}, required-interface=VeDMAB_y_StatusByte_HybridGenPerf_Slip
      VeDMAB_y_StatusByte_StarterGenMechPerf_Slip: nonqueued-receiver-com-spec{data-element=Value, init-value=0}, required-interface=VeDMAB_y_StatusByte_StarterGenMechPerf_Slip
      VeDMAB_y_StatusByte_DM_B_I_PwrSplyCkt: nonqueued-receiver-com-spec{data-element=Value, init-value=0}, required-interface=VeDMAB_y_StatusByte_DM_B_I_PwrSplyCkt
      VeDMAB_y_StatusByte_InvData_SGCM: nonqueued-receiver-com-spec{data-element=Value, init-value=0}, required-interface=VeDMAB_y_StatusByte_InvData_SGCM
      VeDMAB_y_StatusByte_LostCommSGCM: nonqueued-receiver-com-spec{data-element=Value, init-value=0}, required-interface=VeDMAB_y_StatusByte_LostCommSGCM
      VeDMAB_y_StatusByte_InvData_DMCM_A_CANC11: nonqueued-receiver-com-spec{data-element=Value, init-value=0}, required-interface=VeDMAB_y_StatusByte_InvData_DMCM_A_CANC11
      VeDMAB_y_StatusByte_InvData_DMCM_A: nonqueued-receiver-com-spec{data-element=Value, init-value=0}, required-interface=VeDMAB_y_StatusByte_InvData_DMCM_A
      VeDMAB_y_StatusByte_InvData_DMCM_B: nonqueued-receiver-com-spec{data-element=Value, init-value=0}, required-interface=VeDMAB_y_StatusByte_InvData_DMCM_B
      VeDMAB_y_StatusByte_InvData_GenrA_CM: nonqueued-receiver-com-spec{data-element=Value, init-value=0}, required-interface=VeDMAB_y_StatusByte_InvData_GenrA_CM
      VeDMAB_y_StatusByte_InvData_MCPA_CANC11: nonqueued-receiver-com-spec{data-element=Value, init-value=0}, required-interface=VeDMAB_y_StatusByte_InvData_MCPA_CANC11
      VeDMAB_y_StatusByte_InvData_MCPB_CANC11: nonqueued-receiver-com-spec{data-element=Value, init-value=0}, required-interface=VeDMAB_y_StatusByte_InvData_MCPB_CANC11
      VeDMAB_y_StatusByte_LoC_MCPA_CANC11: nonqueued-receiver-com-spec{data-element=Value, init-value=0}, required-interface=VeDMAB_y_StatusByte_LoC_MCPA_CANC11
      VeDMAB_y_StatusByte_LoC_MCPB_CANC11: nonqueued-receiver-com-spec{data-element=Value, init-value=0}, required-interface=VeDMAB_y_StatusByte_LoC_MCPB_CANC11
      VeDMAB_y_StatusByte_LostCommDMCM_2: nonqueued-receiver-com-spec{data-element=Value, init-value=0}, required-interface=VeDMAB_y_StatusByte_LostCommDMCM_2
      VeDMAB_y_StatusByte_LostComm_DMCM_A_CANC11: nonqueued-receiver-com-spec{data-element=Value, init-value=0}, required-interface=VeDMAB_y_StatusByte_LostComm_DMCM_A_CANC11
      VeDMAB_y_StatusByte_LostComm_DMCM_A: nonqueued-receiver-com-spec{data-element=Value, init-value=0}, required-interface=VeDMAB_y_StatusByte_LostComm_DMCM_A
      VeDMAB_y_StatusByte_LostComm_GenrA_CM: nonqueued-receiver-com-spec{data-element=Value, init-value=0}, required-interface=VeDMAB_y_StatusByte_LostComm_GenrA_CM
      VeDMAB_y_StatusByte_BattCoolPmpOveSpd: nonqueued-receiver-com-spec{data-element=Value, init-value=0}, required-interface=VeDMAB_y_StatusByte_BattCoolPmpOveSpd
      VeDMAB_y_StatusByte_ClntTempTooHigh: nonqueued-receiver-com-spec{data-element=Value, init-value=0}, required-interface=VeDMAB_y_StatusByte_ClntTempTooHigh
      VeDMAB_y_StatusByte_LIN{1..3}_BusOff: nonqueued-receiver-com-spec{data-element=Value, init-value=0}, required-interface=VeDMAB_y_StatusByte_LIN{1..3}_BusOff
      VeDMAB_y_StatusByte_LostCommMtrElectCoolPmpA: nonqueued-receiver-com-spec{data-element=Value, init-value=0}, required-interface=VeDMAB_y_StatusByte_LostCommMtrElectCoolPmpA
      VeDMAB_y_StatusByte_LostCommMtrElectCoolPmpB: nonqueued-receiver-com-spec{data-element=Value, init-value=0}, required-interface=VeDMAB_y_StatusByte_LostCommMtrElectCoolPmpB
      VeDMAB_y_StatusByte_MtrElect_CoolPumAOvrSpd: nonqueued-receiver-com-spec{data-element=Value, init-value=0}, required-interface=VeDMAB_y_StatusByte_MtrElect_CoolPumAOvrSpd
      VeDMAB_y_StatusByte_AHCP_LostCommABS: nonqueued-receiver-com-spec{data-element=Value, init-value=0}, required-interface=VeDMAB_y_StatusByte_AHCP_LostCommABS
      VeDMAB_y_StatusByte_InvData_ABS: nonqueued-receiver-com-spec{data-element=Value, init-value=0}, required-interface=VeDMAB_y_StatusByte_InvData_ABS
      VeDMAB_y_StatusByte_InvData_BCM: nonqueued-receiver-com-spec{data-element=Value, init-value=0}, required-interface=VeDMAB_y_StatusByte_InvData_BCM
      VeDMAB_y_StatusByte_InvData_ESM_BusB: nonqueued-receiver-com-spec{data-element=Value, init-value=0}, required-interface=VeDMAB_y_StatusByte_InvData_ESM_BusB
      VeDMAB_y_StatusByte_InvData_ESM: nonqueued-receiver-com-spec{data-element=Value, init-value=0}, required-interface=VeDMAB_y_StatusByte_InvData_ESM
      VeDMAB_y_StatusByte_InvData_TCM_BusB: nonqueued-receiver-com-spec{data-element=Value, init-value=0}, required-interface=VeDMAB_y_StatusByte_InvData_TCM_BusB
      VeDMAB_y_StatusByte_InvData_TCM: nonqueued-receiver-com-spec{data-element=Value, init-value=0}, required-interface=VeDMAB_y_StatusByte_InvData_TCM
      VeDMAB_y_StatusByte_LostCommABSCM: nonqueued-receiver-com-spec{data-element=Value, init-value=0}, required-interface=VeDMAB_y_StatusByte_LostCommABSCM
      VeDMAB_y_StatusByte_LostCommABS_BusB: nonqueued-receiver-com-spec{data-element=Value, init-value=0}, required-interface=VeDMAB_y_StatusByte_LostCommABS_BusB
      VeDMAB_y_StatusByte_LostCommBCM: nonqueued-receiver-com-spec{data-element=Value, init-value=0}, required-interface=VeDMAB_y_StatusByte_LostCommBCM
      VeDMAB_y_StatusByte_LostCommESM_BusB: nonqueued-receiver-com-spec{data-element=Value, init-value=0}, required-interface=VeDMAB_y_StatusByte_LostCommESM_BusB
      VeDMAB_y_StatusByte_LostCommISM: nonqueued-receiver-com-spec{data-element=Value, init-value=0}, required-interface=VeDMAB_y_StatusByte_LostCommISM
      VeDMAB_y_StatusByte_LostCommTrans_EPT: nonqueued-receiver-com-spec{data-element=Value, init-value=0}, required-interface=VeDMAB_y_StatusByte_LostCommTrans_EPT
      VeDMAB_y_StatusByte_LostCommTrans: nonqueued-receiver-com-spec{data-element=Value, init-value=0}, required-interface=VeDMAB_y_StatusByte_LostCommTrans
      VeDMAB_y_StatusByte_VehSpd_OSS_Corr: nonqueued-receiver-com-spec{data-element=Value, init-value=0}, required-interface=VeDMAB_y_StatusByte_VehSpd_OSS_Corr
      VeDCAB_b_CreepModeReq_DidWrite: nonqueued-receiver-com-spec{data-element=Value, init-value=0}, required-interface=VeDCAB_b_CreepModeReq_DidWrite
      VeINVR_b_DMPI_TempStopFlag: nonqueued-receiver-com-spec{data-element=Value, init-value=0}, required-interface=VeINVR_b_DMPI_TempStopFlag
      VeBPCR_T_BatModTmp: nonqueued-receiver-com-spec{data-element=Value, init-value=0}, required-interface=VeBPCR_T_BatModTmp
      VeDMDR_e_TurtleMdSts: nonqueued-receiver-com-spec{data-element=Value, init-value=CeDMDR_e_No_Turtle_Mode}, required-interface=VeDMDR_e_TurtleMdSts
      VeHMIR_b_DriveReady: nonqueued-receiver-com-spec{data-element=Value, init-value=0}, required-interface=VeHMIR_b_DriveReady
      VeDMAB_y_StatusByte_InvData_ABS_BusB: nonqueued-receiver-com-spec{data-element=Value, init-value=0}, required-interface=VeDMAB_y_StatusByte_InvData_ABS_BusB
      VeDMAB_y_StatusByte_InvData_CANC2_BCM: nonqueued-receiver-com-spec{data-element=Value, init-value=0}, required-interface=VeDMAB_y_StatusByte_InvData_CANC2_BCM
      VeDMAB_y_StatusByte_InvData_CADM: nonqueued-receiver-com-spec{data-element=Value, init-value=0}, required-interface=VeDMAB_y_StatusByte_InvData_CADM
      VeDMAB_y_StatusByte_LosComm_CADM: nonqueued-receiver-com-spec{data-element=Value, init-value=0}, required-interface=VeDMAB_y_StatusByte_LosComm_CADM
      VeDMAB_y_StatusByte_InvData_RHSC2: nonqueued-receiver-com-spec{data-element=Value, init-value=0}, required-interface=VeDMAB_y_StatusByte_InvData_RHSC2
      VeDMAB_y_StatusByte_LostCommRHSC2: nonqueued-receiver-com-spec{data-element=Value, init-value=0}, required-interface=VeDMAB_y_StatusByte_LostCommRHSC2
      VeDMAB_y_StatusByte_RF_WHL_HubDisConActPosSnsr: nonqueued-receiver-com-spec{data-element=Value, init-value=0}, required-interface=VeDMAB_y_StatusByte_RF_WHL_HubDisConActPosSnsr
      VeDMAB_y_StatusByte_RF_WHL_HubDisConActPosSnsrCktPerf: nonqueued-receiver-com-spec{data-element=Value, init-value=0}, required-interface=VeDMAB_y_StatusByte_RF_WHL_HubDisConActPosSnsrCktPerf
      VeDMAB_y_StatusByte_LF_WHL_HubDisConActPosSnsr: nonqueued-receiver-com-spec{data-element=Value, init-value=0}, required-interface=VeDMAB_y_StatusByte_LF_WHL_HubDisConActPosSnsr
      VeDMAB_y_StatusByte_LF_WHL_HubDisConActPosSnsrCktPerf: nonqueued-receiver-com-spec{data-element=Value, init-value=0}, required-interface=VeDMAB_y_StatusByte_LF_WHL_HubDisConActPosSnsrCktPerf
      VeDMAB_y_StatusByte_RF_WHL_HubDisConActCntrl: nonqueued-receiver-com-spec{data-element=Value, init-value=0}, required-interface=VeDMAB_y_StatusByte_RF_WHL_HubDisConActCntrl
      VeDMAB_y_StatusByte_LF_WHL_HubDisConActCntrl: nonqueued-receiver-com-spec{data-element=Value, init-value=0}, required-interface=VeDMAB_y_StatusByte_LF_WHL_HubDisConActCntrl
      VeDMAB_y_StatusByte_PwrtrnOilPmp1OvrSpd: nonqueued-receiver-com-spec{data-element=Value, init-value=0}, required-interface=VeDMAB_y_StatusByte_PwrtrnOilPmp1OvrSpd
      VeDMAB_y_StatusByte_LostCommPwrtrn_OilPmp1: nonqueued-receiver-com-spec{data-element=Value, init-value=0}, required-interface=VeDMAB_y_StatusByte_LostCommPwrtrn_OilPmp1
      VeDMAB_y_StatusByte_PwrtrnOilPmp2OvrSpd: nonqueued-receiver-com-spec{data-element=Value, init-value=0}, required-interface=VeDMAB_y_StatusByte_PwrtrnOilPmp2OvrSpd
      VeDMAB_y_StatusByte_LostCommPwrtrn_OilPmp2: nonqueued-receiver-com-spec{data-element=Value, init-value=0}, required-interface=VeDMAB_y_StatusByte_LostCommPwrtrn_OilPmp2
      VeADIR_e_WEDMechFailure_Sts: nonqueued-receiver-com-spec{data-element=Value, init-value=CeADIR_e_BreakageNotTested}, required-interface=VeADIR_e_WEDMechFailure_Sts
      VeINVR_e_BstCnvtrFailSts: nonqueued-receiver-com-spec{data-element=Value, init-value=CeINVR_e_BstCnvFailStsNormal}, required-interface=VeINVR_e_BstCnvtrFailSts
      VeINVR_b_BstCnvtrFailStsFA: nonqueued-receiver-com-spec{data-element=Value, init-value=0}, required-interface=VeINVR_b_BstCnvtrFailStsFA
    99 x provide port:
      VeSRAR_b_Inhibit_NeutralCmnd: nonqueued-sender-com-spec{data-element=Value, init-value=0}, provided-interface=VeSRAR_b_Inhibit_NeutralCmnd
      VeSRAR_b_Inhibit_Mode1Cmnd: nonqueued-sender-com-spec{data-element=Value, init-value=0}, provided-interface=VeSRAR_b_Inhibit_Mode1Cmnd
      VeSRAR_b_Inhibit_Mode2Cmnd: nonqueued-sender-com-spec{data-element=Value, init-value=0}, provided-interface=VeSRAR_b_Inhibit_Mode2Cmnd
      VeSRAR_b_Inhibit_Gear{1..4}Cmnd: nonqueued-sender-com-spec{data-element=Value, init-value=0}, provided-interface=VeSRAR_b_Inhibit_Gear{1..4}Cmnd
      VeSRAR_b_RegenBrkInhb: nonqueued-sender-com-spec{data-element=Value, init-value=0}, provided-interface=VeSRAR_b_RegenBrkInhb
      VeSRAR_b_HybPwrtrnRdcdPerfCmnd: nonqueued-sender-com-spec{data-element=Value, init-value=0}, provided-interface=VeSRAR_b_HybPwrtrnRdcdPerfCmnd
      VeSRAR_b_ReducedPerfMode: nonqueued-sender-com-spec{data-element=Value, init-value=0}, provided-interface=VeSRAR_b_ReducedPerfMode
      VeSRAR_b_ReducedPerfMode2: nonqueued-sender-com-spec{data-element=Value, init-value=0}, provided-interface=VeSRAR_b_ReducedPerfMode2
      VeSRAR_b_CreepTorqMode: nonqueued-sender-com-spec{data-element=Value, init-value=0}, provided-interface=VeSRAR_b_CreepTorqMode
      VeSRAR_b_limitInputTrq: nonqueued-sender-com-spec{data-element=Value, init-value=0}, provided-interface=VeSRAR_b_limitInputTrq
      VeSRAR_b_FltShtDwnBPClsdCmnd: nonqueued-sender-com-spec{data-element=Value, init-value=0}, provided-interface=VeSRAR_b_FltShtDwnBPClsdCmnd
      VeSRAR_b_FltShtDwnCmnd: nonqueued-sender-com-spec{data-element=Value, init-value=0}, provided-interface=VeSRAR_b_FltShtDwnCmnd
      VeSRAR_e_EngStrtStpOvrrd: nonqueued-sender-com-spec{data-element=Value, init-value=CeSTRR_e_NoOvrrd}, provided-interface=VeSRAR_e_EngStrtStpOvrrd
      VeSRAR_b_LimTrans: nonqueued-sender-com-spec{data-element=Value, init-value=0}, provided-interface=VeSRAR_b_LimTrans
      VeSRAR_b_EngStrtStpEngShtDwn: nonqueued-sender-com-spec{data-element=Value, init-value=0}, provided-interface=VeSRAR_b_EngStrtStpEngShtDwn
      VeSRAR_b_EngStrtStpEngRun: nonqueued-sender-com-spec{data-element=Value, init-value=0}, provided-interface=VeSRAR_b_EngStrtStpEngRun
      VeSRAR_b_FltShtDwnCmndRet: nonqueued-sender-com-spec{data-element=Value, init-value=0}, provided-interface=VeSRAR_b_FltShtDwnCmndRet
      VeSRAR_b_RA_Actv: nonqueued-sender-com-spec{data-element=Value, init-value=0}, provided-interface=VeSRAR_b_RA_Actv
      VeSRAR_b_TCMCommFltM1Only: nonqueued-sender-com-spec{data-element=Value, init-value=0}, provided-interface=VeSRAR_b_TCMCommFltM1Only
      VeSRAR_b_TCMCommFltM2Only: nonqueued-sender-com-spec{data-element=Value, init-value=0}, provided-interface=VeSRAR_b_TCMCommFltM2Only
      VeSRAR_b_Inhibit_GearsCmnd: nonqueued-sender-com-spec{data-element=Value, init-value=0}, provided-interface=VeSRAR_b_Inhibit_GearsCmnd
      VeSRAR_y_RemedialActionHist: nonqueued-sender-com-spec{data-element=Value, init-value=0}, provided-interface=VeSRAR_y_RemedialActionHist
      VeSRAR_b_HCP_Remedial_Stop: nonqueued-sender-com-spec{data-element=Value, init-value=0}, provided-interface=VeSRAR_b_HCP_Remedial_Stop
      VeSRAR_b_DrvAllwd: nonqueued-sender-com-spec{data-element=Value, init-value=0}, provided-interface=VeSRAR_b_DrvAllwd
      VeSRAR_b_NeutAllwd: nonqueued-sender-com-spec{data-element=Value, init-value=0}, provided-interface=VeSRAR_b_NeutAllwd
      VeSRAR_k_ReasonStopCharging: nonqueued-sender-com-spec{data-element=Value, init-value=0}, provided-interface=VeSRAR_k_ReasonStopCharging
      VeSRAR_e_EngStrtType: nonqueued-sender-com-spec{data-element=Value, init-value=CeSRAR_e_NoStrt}, provided-interface=VeSRAR_e_EngStrtType
      VeSRAR_b_OutOfFuelSOCShtDwn: nonqueued-sender-com-spec{data-element=Value, init-value=0}, provided-interface=VeSRAR_b_OutOfFuelSOCShtDwn
      VeSRAR_b_HybFeedback_ECM: nonqueued-sender-com-spec{data-element=Value, init-value=0}, provided-interface=VeSRAR_b_HybFeedback_ECM
      VeSRAR_n_HCPMaxEngRPM: nonqueued-sender-com-spec{data-element=Value, init-value=0}, provided-interface=VeSRAR_n_HCPMaxEngRPM
      VeSRAR_scl_DisableAEMD: nonqueued-sender-com-spec{data-element=Value, init-value=0}, provided-interface=VeSRAR_scl_DisableAEMD
      VeSRAR_b_DsblInvA: nonqueued-sender-com-spec{data-element=Value, init-value=0}, provided-interface=VeSRAR_b_DsblInvA
      VeSRAR_b_DsblInvB: nonqueued-sender-com-spec{data-element=Value, init-value=0}, provided-interface=VeSRAR_b_DsblInvB
      VeSRAR_b_OpnBattCntctr: nonqueued-sender-com-spec{data-element=Value, init-value=0}, provided-interface=VeSRAR_b_OpnBattCntctr
      VeSRAR_e_EPB_Hold_Req: nonqueued-sender-com-spec{data-element=Value, init-value=CeTRGR_e_EPBReq_NA}, provided-interface=VeSRAR_e_EPB_Hold_Req
      VeSRAR_b_EngShutDwn_EngOffKeyStrtinNeutralOnly: nonqueued-sender-com-spec{data-element=Value, init-value=0}, provided-interface=VeSRAR_b_EngShutDwn_EngOffKeyStrtinNeutralOnly
      VeSRAR_b_FltShtDwnBPClsdCmnd_bfDly: nonqueued-sender-com-spec{data-element=Value, init-value=0}, provided-interface=VeSRAR_b_FltShtDwnBPClsdCmnd_bfDly
      VeSRAR_b_FltShtDwnCmnd_bfDly: nonqueued-sender-com-spec{data-element=Value, init-value=0}, provided-interface=VeSRAR_b_FltShtDwnCmnd_bfDly
      VeSRAR_b_DsblPSA_PlgIn_EngOn: nonqueued-sender-com-spec{data-element=Value, init-value=0}, provided-interface=VeSRAR_b_DsblPSA_PlgIn_EngOn
      VeSRAR_b_CAN_HybFeedback_ECM: nonqueued-sender-com-spec{data-element=Value, init-value=0}, provided-interface=VeSRAR_b_CAN_HybFeedback_ECM
      VeSRAR_b_EngStrtStpEngShtDwnIntm: nonqueued-sender-com-spec{data-element=Value, init-value=0}, provided-interface=VeSRAR_b_EngStrtStpEngShtDwnIntm
      VeSRAR_b_TempEngShtDwnEnbl: nonqueued-sender-com-spec{data-element=Value, init-value=0}, provided-interface=VeSRAR_b_TempEngShtDwnEnbl
      VeSRAR_b_SPIFlt: nonqueued-sender-com-spec{data-element=Value, init-value=0}, provided-interface=VeSRAR_b_SPIFlt
      VeSRAR_b_SharedMemFlt: nonqueued-sender-com-spec{data-element=Value, init-value=0}, provided-interface=VeSRAR_b_SharedMemFlt
      VeSRAR_b_StpCharging: nonqueued-sender-com-spec{data-element=Value, init-value=0}, provided-interface=VeSRAR_b_StpCharging
      VeSRAR_b_VehShutoffSoon: nonqueued-sender-com-spec{data-element=Value, init-value=0}, provided-interface=VeSRAR_b_VehShutoffSoon
      VeSRAR_b_Dsbl_MtrB_IdlSpd: nonqueued-sender-com-spec{data-element=Value, init-value=0}, provided-interface=VeSRAR_b_Dsbl_MtrB_IdlSpd
      VeSRAR_b_Inhibit_DriveMode: nonqueued-sender-com-spec{data-element=Value, init-value=0}, provided-interface=VeSRAR_b_Inhibit_DriveMode
      VeSRAR_b_Inhibit_AWD_TerrainMode: nonqueued-sender-com-spec{data-element=Value, init-value=0}, provided-interface=VeSRAR_b_Inhibit_AWD_TerrainMode
      VeSRAR_b_DsblAECoasting: nonqueued-sender-com-spec{data-element=Value, init-value=0}, provided-interface=VeSRAR_b_DsblAECoasting
      VeSRAR_b_LV12PwrFreeReq_PHEV: nonqueued-sender-com-spec{data-element=Value, init-value=0}, provided-interface=VeSRAR_b_LV12PwrFreeReq_PHEV
      VeSRAR_b_TrqEnblReq_TCM_PHEV: nonqueued-sender-com-spec{data-element=Value, init-value=0}, provided-interface=VeSRAR_b_TrqEnblReq_TCM_PHEV
      VeSRAR_i_LHOM_Trans_PHEV: nonqueued-sender-com-spec{data-element=Value, init-value=0}, provided-interface=VeSRAR_i_LHOM_Trans_PHEV
      VeSRAR_b_DerateSumTrqMax: nonqueued-sender-com-spec{data-element=Value, init-value=0}, provided-interface=VeSRAR_b_DerateSumTrqMax
      VeSRAR_b_Inhibit_RWD_TerrainMode: nonqueued-sender-com-spec{data-element=Value, init-value=0}, provided-interface=VeSRAR_b_Inhibit_RWD_TerrainMode
      VeSRAR_b_HybAlternatorMd: nonqueued-sender-com-spec{data-element=Value, init-value=0}, provided-interface=VeSRAR_b_HybAlternatorMd
      VeSRAR_b_InhibitGSI: nonqueued-sender-com-spec{data-element=Value, init-value=0}, provided-interface=VeSRAR_b_InhibitGSI
      VeSRAR_e_LoCHCP_BPCM_ePT: nonqueued-sender-com-spec{data-element=Value, init-value=CeSRAR_e_NoFaultHCPBPCM_ePT}, provided-interface=VeSRAR_e_LoCHCP_BPCM_ePT
      VeSRAR_e_LoCHCP_TCMECM_CANC: nonqueued-sender-com-spec{data-element=Value, init-value=0}, provided-interface=VeSRAR_e_LoCHCP_TCMECM_CANC
      VeSRAR_e_LoCAHCP_BSM_CANC2: nonqueued-sender-com-spec{data-element=Value, init-value=CeSRAR_e_NoFaultHCPBSM_C2}, provided-interface=VeSRAR_e_LoCAHCP_BSM_CANC2
      VeSRAR_e_LoCHCP_TCMECM_ePT: nonqueued-sender-com-spec{data-element=Value, init-value=CeSRAR_e_NoFaultHCPTCMECM_ePT}, provided-interface=VeSRAR_e_LoCHCP_TCMECM_ePT
      VeSRAR_e_LoCHCP_BSM_CANC: nonqueued-sender-com-spec{data-element=Value, init-value=CeSRAR_e_NoFaultHCPBSM_C1}, provided-interface=VeSRAR_e_LoCHCP_BSM_CANC
      VeSRAR_b_InhibitCruise: nonqueued-sender-com-spec{data-element=Value, init-value=0}, provided-interface=VeSRAR_b_InhibitCruise
      VeSRAR_b_ThmlLoadShdActv: nonqueued-sender-com-spec{data-element=Value, init-value=0}, provided-interface=VeSRAR_b_ThmlLoadShdActv
      VeSRAR_b_OnePedalDriveDsbl: nonqueued-sender-com-spec{data-element=Value, init-value=0}, provided-interface=VeSRAR_b_OnePedalDriveDsbl
      VeSRAR_b_Veh_Spd_Lmtd: nonqueued-sender-com-spec{data-element=Value, init-value=0}, provided-interface=VeSRAR_b_Veh_Spd_Lmtd
      VeSRAR_b_PerfLmtd_StpSfly: nonqueued-sender-com-spec{data-element=Value, init-value=0}, provided-interface=VeSRAR_b_PerfLmtd_StpSfly
      VeSRAR_b_InhibitActvSpdLmtr: nonqueued-sender-com-spec{data-element=Value, init-value=0}, provided-interface=VeSRAR_b_InhibitActvSpdLmtr
      VeSRAR_b_Popup_Msg1: nonqueued-sender-com-spec{data-element=Value, init-value=0}, provided-interface=VeSRAR_b_Popup_Msg1
      VeSRAR_b_Popup_Msg9: nonqueued-sender-com-spec{data-element=Value, init-value=0}, provided-interface=VeSRAR_b_Popup_Msg9
      VeSRAR_b_Popup_Msg14: nonqueued-sender-com-spec{data-element=Value, init-value=0}, provided-interface=VeSRAR_b_Popup_Msg14
      VeSRAR_b_Popup_Msg15: nonqueued-sender-com-spec{data-element=Value, init-value=0}, provided-interface=VeSRAR_b_Popup_Msg15
      VeSRAR_b_MtrBZeroTrqActv: nonqueued-sender-com-spec{data-element=Value, init-value=0}, provided-interface=VeSRAR_b_MtrBZeroTrqActv
      VeSRAR_b_K0AsyncCloseActv: nonqueued-sender-com-spec{data-element=Value, init-value=0}, provided-interface=VeSRAR_b_K0AsyncCloseActv
      VeSRAR_b_InplantCreepModeRqst: nonqueued-sender-com-spec{data-element=Value, init-value=0}, provided-interface=VeSRAR_b_InplantCreepModeRqst
      VeSRAR_b_Dsbl_SL_PID: nonqueued-sender-com-spec{data-element=Value, init-value=0}, provided-interface=VeSRAR_b_Dsbl_SL_PID
      VeSRAR_b_MtrA_AlternatorMdAvbl: nonqueued-sender-com-spec{data-element=Value, init-value=0}, provided-interface=VeSRAR_b_MtrA_AlternatorMdAvbl
      VeSRAR_g_RA_InputSet{1..8}: nonqueued-sender-com-spec{data-element=Value, init-value=0}, provided-interface=VeSRAR_g_RA_InputSet{1..8}
      VeSRAR_b_Inhibit_eBoost: nonqueued-sender-com-spec{data-element=Value, init-value=0}, provided-interface=VeSRAR_b_Inhibit_eBoost
      VeSRAR_b_MtrAZeroTrqActv: nonqueued-sender-com-spec{data-element=Value, init-value=0}, provided-interface=VeSRAR_b_MtrAZeroTrqActv
      VeSRAR_b_MtrCZeroTrqActv: nonqueued-sender-com-spec{data-element=Value, init-value=0}, provided-interface=VeSRAR_b_MtrCZeroTrqActv
      VeSRAR_b_DsblInvC: nonqueued-sender-com-spec{data-element=Value, init-value=0}, provided-interface=VeSRAR_b_DsblInvC
      VeSRAR_b_HMI_LeaveIgnition_ON: nonqueued-sender-com-spec{data-element=Value, init-value=0}, provided-interface=VeSRAR_b_HMI_LeaveIgnition_ON
      VeSRAR_b_Disable_RaceStart: nonqueued-sender-com-spec{data-element=Value, init-value=0}, provided-interface=VeSRAR_b_Disable_RaceStart
      VeSRAR_b_Disable_PwrPanel: nonqueued-sender-com-spec{data-element=Value, init-value=0}, provided-interface=VeSRAR_b_Disable_PwrPanel
      VeSRAR_b_InvrtrShortCntcrWeld: nonqueued-sender-com-spec{data-element=Value, init-value=0}, provided-interface=VeSRAR_b_InvrtrShortCntcrWeld
      VeSRAR_b_Disable_TCaseSpeedSync: nonqueued-sender-com-spec{data-element=Value, init-value=0}, provided-interface=VeSRAR_b_Disable_TCaseSpeedSync
      VeSRAR_b_BSMLoCBusOff_CANC_C2: nonqueued-sender-com-spec{data-element=Value, init-value=0}, provided-interface=VeSRAR_b_BSMLoCBusOff_CANC_C2
      VeSRAR_g_RA_InputSet9: nonqueued-sender-com-spec{data-element=Value, init-value=0}, provided-interface=VeSRAR_g_RA_InputSet9
    12 x require port:
      NeSRAR_e_EngStrtType_DS_Rx: nv-require-com-spec{init-value=0, variable=NeSRAR_e_EngStrtType_DS}, required-interface=NeSRAR_e_EngStrtType_DS
      NeSRAR_g_InputHist_{1..8}_DS_Rx: nv-require-com-spec{init-value=0, variable=NeSRAR_g_InputHist_{1..8}_DS}, required-interface=NeSRAR_g_InputHist_{1..8}_DS
      NeSRAR_d_ReasonStopCharging_DS_Rx: nv-require-com-spec{init-value=0, variable=NeSRAR_d_ReasonStopCharging_DS}, required-interface=NeSRAR_d_ReasonStopCharging_DS
      NeSRAR_d_RemedialActionHist_DS_Rx: nv-require-com-spec{init-value=0, variable=NeSRAR_d_RemedialActionHist_DS}, required-interface=NeSRAR_d_RemedialActionHist_DS
      NeSRAR_g_InputHist_9_DS_Rx: nv-require-com-spec{init-value=0, variable=NeSRAR_g_InputHist_9_DS}, required-interface=NeSRAR_g_InputHist_9_DS
    12 x provide port:
      NeSRAR_e_EngStrtType_DS: nv-provide-com-spec{ram-block-init-value=0, variable=NeSRAR_e_EngStrtType_DS}, provided-interface=NeSRAR_e_EngStrtType_DS
      NeSRAR_g_InputHist_{1..8}_DS: nv-provide-com-spec{ram-block-init-value=0, variable=NeSRAR_g_InputHist_{1..8}_DS}, provided-interface=NeSRAR_g_InputHist_{1..8}_DS
      NeSRAR_d_ReasonStopCharging_DS: nv-provide-com-spec{ram-block-init-value=0, variable=NeSRAR_d_ReasonStopCharging_DS}, provided-interface=NeSRAR_d_ReasonStopCharging_DS
      NeSRAR_d_RemedialActionHist_DS: nv-provide-com-spec{ram-block-init-value=0, variable=NeSRAR_d_RemedialActionHist_DS}, provided-interface=NeSRAR_d_RemedialActionHist_DS
      NeSRAR_g_InputHist_9_DS: nv-provide-com-spec{ram-block-init-value=0, variable=NeSRAR_g_InputHist_9_DS}, provided-interface=NeSRAR_g_InputHist_9_DS
    require port KeTSXR_r_P1f: parameter-require-com-spec{init-value=KeTSXR_r_P1f_KeTSXR_r_P1f:2.55550003051758, parameter=KeTSXR_r_P1f}, required-interface=KeTSXR_r_P1f
    behavior IB_SRAR: data-type-mapping=msADTtoIDTMapping, handle-termination-and-restart=NO-SUPPORT
      timing event Event_MedTEB: start-on-event=SRAR_MedTEB, period=0.01
      init event Event_SRAR_ac_Init: start-on-event=SRAR_ac_Init
      init event Event_PwrOn: start-on-event=SRAR_PwrOn
      init event Event_PwrOff: start-on-event=SRAR_PwrOff
      data received event Event_DIDWrite_CreepModeReq: start-on-event=DIDWrite_CreepModeReq, data=VeDCAB_b_CreepModeReq_DidWrite.Value
      explicit-inter-runnable-variables:
        data VeSRAR_n_HCPMaxEngRPM_write_IRV: category=VALUE, sw-calibration-access=READ-ONLY, type=Float, init-value=0
        data VeDCAB_b_CreepModeReq_DidWrite_out_IRV: category=VALUE, sw-calibration-access=READ-ONLY, type=Boolean, init-value=0
      5 x runnable:
        SRAR_ac_Init
          data-send-points:
            7 x access:
              OUT_VeSRAR_e_EngStrtStpOvrrd_Value: accessed-variable=VeSRAR_e_EngStrtStpOvrrd.Value
              OUT_VeSRAR_e_EngStrtType_Value: accessed-variable=VeSRAR_e_EngStrtType.Value
              OUT_VeSRAR_e_EPB_Hold_Req_Value: accessed-variable=VeSRAR_e_EPB_Hold_Req.Value
              OUT_VeSRAR_e_LoCHCP_BPCM_ePT_Value: accessed-variable=VeSRAR_e_LoCHCP_BPCM_ePT.Value
              OUT_VeSRAR_e_LoCAHCP_BSM_CANC2_Value: accessed-variable=VeSRAR_e_LoCAHCP_BSM_CANC2.Value
              OUT_VeSRAR_e_LoCHCP_TCMECM_ePT_Value: accessed-variable=VeSRAR_e_LoCHCP_TCMECM_ePT.Value
              OUT_VeSRAR_e_LoCHCP_BSM_CANC_Value: accessed-variable=VeSRAR_e_LoCHCP_BSM_CANC.Value
          written-local-variables:
            access WV_VeSRAR_n_HCPMaxEngRPM_write_IRV: accessed-variable=VeSRAR_n_HCPMaxEngRPM_write_IRV
        SRAR_PwrOn
          data-receive-point-by-arguments:
            12 x access:
              IN_NeSRAR_d_ReasonStopCharging_DS_Rx_NeSRAR_d_ReasonStopCharging_DS: accessed-variable=NeSRAR_d_ReasonStopCharging_DS_Rx.NeSRAR_d_ReasonStopCharging_DS
              IN_NeSRAR_d_RemedialActionHist_DS_Rx_NeSRAR_d_RemedialActionHist_DS: accessed-variable=NeSRAR_d_RemedialActionHist_DS_Rx.NeSRAR_d_RemedialActionHist_DS
              IN_NeSRAR_e_EngStrtType_DS_Rx_NeSRAR_e_EngStrtType_DS: accessed-variable=NeSRAR_e_EngStrtType_DS_Rx.NeSRAR_e_EngStrtType_DS
              IN_NeSRAR_g_InputHist_{1..9}_DS_Rx_NeSRAR_g_InputHist_{1..9}_DS: accessed-variable=NeSRAR_g_InputHist_{1..9}_DS_Rx.NeSRAR_g_InputHist_{1..9}_DS
          data-send-points:
            99 x access:
              OUT_VeSRAR_n_HCPMaxEngRPM_Value: accessed-variable=VeSRAR_n_HCPMaxEngRPM.Value
              OUT_VeSRAR_b_CAN_HybFeedback_ECM_Value: accessed-variable=VeSRAR_b_CAN_HybFeedback_ECM.Value
              OUT_VeSRAR_b_Inhibit_NeutralCmnd_Value: accessed-variable=VeSRAR_b_Inhibit_NeutralCmnd.Value
              OUT_VeSRAR_b_Inhibit_Mode1Cmnd_Value: accessed-variable=VeSRAR_b_Inhibit_Mode1Cmnd.Value
              OUT_VeSRAR_b_Inhibit_Mode2Cmnd_Value: accessed-variable=VeSRAR_b_Inhibit_Mode2Cmnd.Value
              OUT_VeSRAR_b_Inhibit_Gear{1..4}Cmnd_Value: accessed-variable=VeSRAR_b_Inhibit_Gear{1..4}Cmnd.Value
              OUT_VeSRAR_b_RegenBrkInhb_Value: accessed-variable=VeSRAR_b_RegenBrkInhb.Value
              OUT_VeSRAR_b_HybPwrtrnRdcdPerfCmnd_Value: accessed-variable=VeSRAR_b_HybPwrtrnRdcdPerfCmnd.Value
              OUT_VeSRAR_b_ReducedPerfMode_Value: accessed-variable=VeSRAR_b_ReducedPerfMode.Value
              OUT_VeSRAR_b_ReducedPerfMode2_Value: accessed-variable=VeSRAR_b_ReducedPerfMode2.Value
              OUT_VeSRAR_b_CreepTorqMode_Value: accessed-variable=VeSRAR_b_CreepTorqMode.Value
              OUT_VeSRAR_b_limitInputTrq_Value: accessed-variable=VeSRAR_b_limitInputTrq.Value
              OUT_VeSRAR_b_FltShtDwnBPClsdCmnd_Value: accessed-variable=VeSRAR_b_FltShtDwnBPClsdCmnd.Value
              OUT_VeSRAR_b_FltShtDwnCmnd_Value: accessed-variable=VeSRAR_b_FltShtDwnCmnd.Value
              OUT_VeSRAR_e_EngStrtStpOvrrd_Value: accessed-variable=VeSRAR_e_EngStrtStpOvrrd.Value
              OUT_VeSRAR_b_LimTrans_Value: accessed-variable=VeSRAR_b_LimTrans.Value
              OUT_VeSRAR_b_EngStrtStpEngShtDwn_Value: accessed-variable=VeSRAR_b_EngStrtStpEngShtDwn.Value
              OUT_VeSRAR_b_EngStrtStpEngRun_Value: accessed-variable=VeSRAR_b_EngStrtStpEngRun.Value
              OUT_VeSRAR_b_FltShtDwnCmndRet_Value: accessed-variable=VeSRAR_b_FltShtDwnCmndRet.Value
              OUT_VeSRAR_b_RA_Actv_Value: accessed-variable=VeSRAR_b_RA_Actv.Value
              OUT_VeSRAR_b_TCMCommFltM1Only_Value: accessed-variable=VeSRAR_b_TCMCommFltM1Only.Value
              OUT_VeSRAR_b_TCMCommFltM2Only_Value: accessed-variable=VeSRAR_b_TCMCommFltM2Only.Value
              OUT_VeSRAR_b_Inhibit_GearsCmnd_Value: accessed-variable=VeSRAR_b_Inhibit_GearsCmnd.Value
              OUT_VeSRAR_y_RemedialActionHist_Value: accessed-variable=VeSRAR_y_RemedialActionHist.Value
              OUT_VeSRAR_b_HCP_Remedial_Stop_Value: accessed-variable=VeSRAR_b_HCP_Remedial_Stop.Value
              OUT_VeSRAR_b_DrvAllwd_Value: accessed-variable=VeSRAR_b_DrvAllwd.Value
              OUT_VeSRAR_b_NeutAllwd_Value: accessed-variable=VeSRAR_b_NeutAllwd.Value
              OUT_VeSRAR_k_ReasonStopCharging_Value: accessed-variable=VeSRAR_k_ReasonStopCharging.Value
              OUT_VeSRAR_e_EngStrtType_Value: accessed-variable=VeSRAR_e_EngStrtType.Value
              OUT_VeSRAR_b_OutOfFuelSOCShtDwn_Value: accessed-variable=VeSRAR_b_OutOfFuelSOCShtDwn.Value
              OUT_VeSRAR_b_HybFeedback_ECM_Value: accessed-variable=VeSRAR_b_HybFeedback_ECM.Value
              OUT_VeSRAR_scl_DisableAEMD_Value: accessed-variable=VeSRAR_scl_DisableAEMD.Value
              OUT_VeSRAR_b_DsblInvA_Value: accessed-variable=VeSRAR_b_DsblInvA.Value
              OUT_VeSRAR_b_DsblInvB_Value: accessed-variable=VeSRAR_b_DsblInvB.Value
              OUT_VeSRAR_b_OpnBattCntctr_Value: accessed-variable=VeSRAR_b_OpnBattCntctr.Value
              OUT_VeSRAR_e_EPB_Hold_Req_Value: accessed-variable=VeSRAR_e_EPB_Hold_Req.Value
              OUT_VeSRAR_b_EngShutDwn_EngOffKeyStrtinNeutralOnly_Value: accessed-variable=VeSRAR_b_EngShutDwn_EngOffKeyStrtinNeutralOnly.Value
              OUT_VeSRAR_b_FltShtDwnBPClsdCmnd_bfDly_Value: accessed-variable=VeSRAR_b_FltShtDwnBPClsdCmnd_bfDly.Value
              OUT_VeSRAR_b_FltShtDwnCmnd_bfDly_Value: accessed-variable=VeSRAR_b_FltShtDwnCmnd_bfDly.Value
              OUT_VeSRAR_b_DsblPSA_PlgIn_EngOn_Value: accessed-variable=VeSRAR_b_DsblPSA_PlgIn_EngOn.Value
              OUT_VeSRAR_b_EngStrtStpEngShtDwnIntm_Value: accessed-variable=VeSRAR_b_EngStrtStpEngShtDwnIntm.Value
              OUT_VeSRAR_b_TempEngShtDwnEnbl_Value: accessed-variable=VeSRAR_b_TempEngShtDwnEnbl.Value
              OUT_VeSRAR_b_SPIFlt_Value: accessed-variable=VeSRAR_b_SPIFlt.Value
              OUT_VeSRAR_b_SharedMemFlt_Value: accessed-variable=VeSRAR_b_SharedMemFlt.Value
              OUT_VeSRAR_b_StpCharging_Value: accessed-variable=VeSRAR_b_StpCharging.Value
              OUT_VeSRAR_b_VehShutoffSoon_Value: accessed-variable=VeSRAR_b_VehShutoffSoon.Value
              OUT_VeSRAR_b_Dsbl_MtrB_IdlSpd_Value: accessed-variable=VeSRAR_b_Dsbl_MtrB_IdlSpd.Value
              OUT_VeSRAR_b_Inhibit_DriveMode_Value: accessed-variable=VeSRAR_b_Inhibit_DriveMode.Value
              OUT_VeSRAR_b_Inhibit_AWD_TerrainMode_Value: accessed-variable=VeSRAR_b_Inhibit_AWD_TerrainMode.Value
              OUT_VeSRAR_b_DsblAECoasting_Value: accessed-variable=VeSRAR_b_DsblAECoasting.Value
              OUT_VeSRAR_b_LV12PwrFreeReq_PHEV_Value: accessed-variable=VeSRAR_b_LV12PwrFreeReq_PHEV.Value
              OUT_VeSRAR_b_TrqEnblReq_TCM_PHEV_Value: accessed-variable=VeSRAR_b_TrqEnblReq_TCM_PHEV.Value
              OUT_VeSRAR_i_LHOM_Trans_PHEV_Value: accessed-variable=VeSRAR_i_LHOM_Trans_PHEV.Value
              OUT_VeSRAR_b_DerateSumTrqMax_Value: accessed-variable=VeSRAR_b_DerateSumTrqMax.Value
              OUT_VeSRAR_b_Inhibit_RWD_TerrainMode_Value: accessed-variable=VeSRAR_b_Inhibit_RWD_TerrainMode.Value
              OUT_VeSRAR_b_HybAlternatorMd_Value: accessed-variable=VeSRAR_b_HybAlternatorMd.Value
              OUT_VeSRAR_b_InhibitGSI_Value: accessed-variable=VeSRAR_b_InhibitGSI.Value
              OUT_VeSRAR_e_LoCHCP_BPCM_ePT_Value: accessed-variable=VeSRAR_e_LoCHCP_BPCM_ePT.Value
              OUT_VeSRAR_e_LoCHCP_TCMECM_CANC_Value: accessed-variable=VeSRAR_e_LoCHCP_TCMECM_CANC.Value
              OUT_VeSRAR_e_LoCAHCP_BSM_CANC2_Value: accessed-variable=VeSRAR_e_LoCAHCP_BSM_CANC2.Value
              OUT_VeSRAR_e_LoCHCP_TCMECM_ePT_Value: accessed-variable=VeSRAR_e_LoCHCP_TCMECM_ePT.Value
              OUT_VeSRAR_e_LoCHCP_BSM_CANC_Value: accessed-variable=VeSRAR_e_LoCHCP_BSM_CANC.Value
              OUT_VeSRAR_b_InhibitCruise_Value: accessed-variable=VeSRAR_b_InhibitCruise.Value
              OUT_VeSRAR_b_ThmlLoadShdActv_Value: accessed-variable=VeSRAR_b_ThmlLoadShdActv.Value
              OUT_VeSRAR_b_OnePedalDriveDsbl_Value: accessed-variable=VeSRAR_b_OnePedalDriveDsbl.Value
              OUT_VeSRAR_b_Veh_Spd_Lmtd_Value: accessed-variable=VeSRAR_b_Veh_Spd_Lmtd.Value
              OUT_VeSRAR_b_PerfLmtd_StpSfly_Value: accessed-variable=VeSRAR_b_PerfLmtd_StpSfly.Value
              OUT_VeSRAR_b_InhibitActvSpdLmtr_Value: accessed-variable=VeSRAR_b_InhibitActvSpdLmtr.Value
              OUT_VeSRAR_b_Popup_Msg1_Value: accessed-variable=VeSRAR_b_Popup_Msg1.Value
              OUT_VeSRAR_b_Popup_Msg9_Value: accessed-variable=VeSRAR_b_Popup_Msg9.Value
              OUT_VeSRAR_b_Popup_Msg14_Value: accessed-variable=VeSRAR_b_Popup_Msg14.Value
              OUT_VeSRAR_b_Popup_Msg15_Value: accessed-variable=VeSRAR_b_Popup_Msg15.Value
              OUT_VeSRAR_b_MtrBZeroTrqActv_Value: accessed-variable=VeSRAR_b_MtrBZeroTrqActv.Value
              OUT_VeSRAR_b_K0AsyncCloseActv_Value: accessed-variable=VeSRAR_b_K0AsyncCloseActv.Value
              OUT_VeSRAR_b_InplantCreepModeRqst_Value: accessed-variable=VeSRAR_b_InplantCreepModeRqst.Value
              OUT_VeSRAR_b_Dsbl_SL_PID_Value: accessed-variable=VeSRAR_b_Dsbl_SL_PID.Value
              OUT_VeSRAR_b_MtrA_AlternatorMdAvbl_Value: accessed-variable=VeSRAR_b_MtrA_AlternatorMdAvbl.Value
              OUT_VeSRAR_g_RA_InputSet{1..8}_Value: accessed-variable=VeSRAR_g_RA_InputSet{1..8}.Value
              OUT_VeSRAR_b_Inhibit_eBoost_Value: accessed-variable=VeSRAR_b_Inhibit_eBoost.Value
              OUT_VeSRAR_b_MtrAZeroTrqActv_Value: accessed-variable=VeSRAR_b_MtrAZeroTrqActv.Value
              OUT_VeSRAR_b_MtrCZeroTrqActv_Value: accessed-variable=VeSRAR_b_MtrCZeroTrqActv.Value
              OUT_VeSRAR_b_DsblInvC_Value: accessed-variable=VeSRAR_b_DsblInvC.Value
              OUT_VeSRAR_b_HMI_LeaveIgnition_ON_Value: accessed-variable=VeSRAR_b_HMI_LeaveIgnition_ON.Value
              OUT_VeSRAR_b_Disable_RaceStart_Value: accessed-variable=VeSRAR_b_Disable_RaceStart.Value
              OUT_VeSRAR_b_Disable_PwrPanel_Value: accessed-variable=VeSRAR_b_Disable_PwrPanel.Value
              OUT_VeSRAR_b_InvrtrShortCntcrWeld_Value: accessed-variable=VeSRAR_b_InvrtrShortCntcrWeld.Value
              OUT_VeSRAR_b_Disable_TCaseSpeedSync_Value: accessed-variable=VeSRAR_b_Disable_TCaseSpeedSync.Value
              OUT_VeSRAR_b_BSMLoCBusOff_CANC_C2_Value: accessed-variable=VeSRAR_b_BSMLoCBusOff_CANC_C2.Value
              OUT_VeSRAR_g_RA_InputSet9_Value: accessed-variable=VeSRAR_g_RA_InputSet9.Value
          written-local-variables:
            access WV_VeDCAB_b_CreepModeReq_DidWrite_out_IRV: accessed-variable=VeDCAB_b_CreepModeReq_DidWrite_out_IRV
            access WV_VeSRAR_n_HCPMaxEngRPM_write_IRV: accessed-variable=VeSRAR_n_HCPMaxEngRPM_write_IRV
        SRAR_MedTEB
          data-receive-point-by-arguments:
            294 x access:
              IN_VeADIR_b_LftWEDClosingFail_Value: accessed-variable=VeADIR_b_LftWEDClosingFail.Value
              IN_VeADIR_b_LftWEDOpeningFail_Value: accessed-variable=VeADIR_b_LftWEDOpeningFail.Value
              IN_VeADIR_b_RtWEDClosingFail_Value: accessed-variable=VeADIR_b_RtWEDClosingFail.Value
              IN_VeADIR_b_RtWEDOpeningFail_Value: accessed-variable=VeADIR_b_RtWEDOpeningFail.Value
              IN_VeADIR_e_WEDMechFailure_Sts_Value: accessed-variable=VeADIR_e_WEDMechFailure_Sts.Value
              IN_VeAPSR_b_AccelPedalEffPositionFA_Value: accessed-variable=VeAPSR_b_AccelPedalEffPositionFA.Value
              IN_VeAPSR_e_Lv1PVMode_Value: accessed-variable=VeAPSR_e_Lv1PVMode.Value
              IN_VeATRR_M_OutputTorqReqImmed_Value: accessed-variable=VeATRR_M_OutputTorqReqImmed.Value
              IN_VeBPCR_Pct_HV_BatPackSOC_Arb_Value: accessed-variable=VeBPCR_Pct_HV_BatPackSOC_Arb.Value
              IN_VeBPCR_T_BatModTmp_Value: accessed-variable=VeBPCR_T_BatModTmp.Value
              IN_VeBPCR_b_BPCM_CommFailFA_Value: accessed-variable=VeBPCR_b_BPCM_CommFailFA.Value
              IN_VeBPCR_b_HVBatCntctrWeld_Qualifier_Value: accessed-variable=VeBPCR_b_HVBatCntctrWeld_Qualifier.Value
              IN_VeBPCR_b_HVBatCntrWeld_ImpdOpn_Value: accessed-variable=VeBPCR_b_HVBatCntrWeld_ImpdOpn.Value
              IN_VeBPCR_b_HV_BatCntctrOpenPending_Value: accessed-variable=VeBPCR_b_HV_BatCntctrOpenPending.Value
              IN_VeBPCR_b_HV_BatCntctrOpenReq_Value: accessed-variable=VeBPCR_b_HV_BatCntctrOpenReq.Value
              IN_VeBPCR_b_HV_BatCurrSFA_Value: accessed-variable=VeBPCR_b_HV_BatCurrSFA.Value
              IN_VeBPCR_b_HV_BatMaxModTmpSFA_Value: accessed-variable=VeBPCR_b_HV_BatMaxModTmpSFA.Value
              IN_VeBPCR_b_HV_BatPackSOC_SFA_Value: accessed-variable=VeBPCR_b_HV_BatPackSOC_SFA.Value
              IN_VeBPCR_b_HV_BatVoltModMaxSFA_Value: accessed-variable=VeBPCR_b_HV_BatVoltModMaxSFA.Value
              IN_VeBPCR_b_PwrLimON_Value: accessed-variable=VeBPCR_b_PwrLimON.Value
              IN_VeBPCR_b_ThrmlRnawyFlg_Value: accessed-variable=VeBPCR_b_ThrmlRnawyFlg.Value
              IN_VeBPCR_e_BPCM_CommFail_Value: accessed-variable=VeBPCR_e_BPCM_CommFail.Value
              IN_VeBRKR_b_ABSActive_Value: accessed-variable=VeBRKR_b_ABSActive.Value
              IN_VeBRKR_b_AeCoastReady_Value: accessed-variable=VeBRKR_b_AeCoastReady.Value
              IN_VeBRKR_b_ImpndSkid_Value: accessed-variable=VeBRKR_b_ImpndSkid.Value
              IN_VeBRKR_e_ComFailBSM_C1CAN_Value: accessed-variable=VeBRKR_e_ComFailBSM_C1CAN.Value
              IN_VeBRKR_e_ComFailBSM_C2CAN_Value: accessed-variable=VeBRKR_e_ComFailBSM_C2CAN.Value
              IN_VeBTQR_M_RegenBrkAxleTrqReq_Value: accessed-variable=VeBTQR_M_RegenBrkAxleTrqReq.Value
              IN_VeBTQR_b_RegenBrkAxleTrqReqFA_Value: accessed-variable=VeBTQR_b_RegenBrkAxleTrqReqFA.Value
              IN_VeCCMR_b_Clch1To4CmdFlt_Value: accessed-variable=VeCCMR_b_Clch1To4CmdFlt.Value
              IN_VeCPDR_b_LTCL_DryRun_FltDtct_Value: accessed-variable=VeCPDR_b_LTCL_DryRun_FltDtct.Value
              IN_VeCPDR_b_LTCL_FunPer_FltDtct_Value: accessed-variable=VeCPDR_b_LTCL_FunPer_FltDtct.Value
              IN_VeCPDR_b_LTPP_FunPer_FltDtct_Value: accessed-variable=VeCPDR_b_LTPP_FunPer_FltDtct.Value
              IN_VeCSDR_b_Clch1_Avail_Value: accessed-variable=VeCSDR_b_Clch1_Avail.Value
              IN_VeCSDR_b_Clch2_Avail_Value: accessed-variable=VeCSDR_b_Clch2_Avail.Value
              IN_VeCSLR_b_NC1_FA_Value: accessed-variable=VeCSLR_b_NC1_FA.Value
              IN_VeCSLR_n_Clch1_RawSlipSpeed_Value: accessed-variable=VeCSLR_n_Clch1_RawSlipSpeed.Value
              IN_VeCSLR_n_Clch2_RawSlipSpeed_Value: accessed-variable=VeCSLR_n_Clch2_RawSlipSpeed.Value
              IN_VeCSVR_b_CanSigVehSpd_FA_Value: accessed-variable=VeCSVR_b_CanSigVehSpd_FA.Value
              IN_VeCSVR_b_TOS_DirectionError_Value: accessed-variable=VeCSVR_b_TOS_DirectionError.Value
              IN_VeCSVR_b_VehSpdVSOSigFailSts_Value: accessed-variable=VeCSVR_b_VehSpdVSOSigFailSts.Value
              IN_VeCSVR_v_VehSpd_Value: accessed-variable=VeCSVR_v_VehSpd.Value
              IN_VeDFIR_b_PostCodeClrDiagDsbl_Value: accessed-variable=VeDFIR_b_PostCodeClrDiagDsbl.Value
              IN_VeDMAB_y_StatusByte_AHCP_LostCommABS_Value: accessed-variable=VeDMAB_y_StatusByte_AHCP_LostCommABS.Value
              IN_VeDMAB_y_StatusByte_BattCoolPmpOveSpd_Value: accessed-variable=VeDMAB_y_StatusByte_BattCoolPmpOveSpd.Value
              IN_VeDMAB_y_StatusByte_CM_AD_Perf_Value: accessed-variable=VeDMAB_y_StatusByte_CM_AD_Perf.Value
              IN_VeDMAB_y_StatusByte_CM_Chksum_Err_Value: accessed-variable=VeDMAB_y_StatusByte_CM_Chksum_Err.Value
              IN_VeDMAB_y_StatusByte_CM_LongTermMemReset_Value: accessed-variable=VeDMAB_y_StatusByte_CM_LongTermMemReset.Value
              IN_VeDMAB_y_StatusByte_CM_MainProc_Value: accessed-variable=VeDMAB_y_StatusByte_CM_MainProc.Value
              IN_VeDMAB_y_StatusByte_CM_OPDActivePerf_Value: accessed-variable=VeDMAB_y_StatusByte_CM_OPDActivePerf.Value
              IN_VeDMAB_y_StatusByte_CM_PLD_Value: accessed-variable=VeDMAB_y_StatusByte_CM_PLD.Value
              IN_VeDMAB_y_StatusByte_CM_ProcessorPerf_Value: accessed-variable=VeDMAB_y_StatusByte_CM_ProcessorPerf.Value
              IN_VeDMAB_y_StatusByte_CM_RAM_Err_Value: accessed-variable=VeDMAB_y_StatusByte_CM_RAM_Err.Value
              IN_VeDMAB_y_StatusByte_CM_ROM_Err_Value: accessed-variable=VeDMAB_y_StatusByte_CM_ROM_Err.Value
              IN_VeDMAB_y_StatusByte_CM_RedundMemPerf_Value: accessed-variable=VeDMAB_y_StatusByte_CM_RedundMemPerf.Value
              IN_VeDMAB_y_StatusByte_ClntTempTooHigh_Value: accessed-variable=VeDMAB_y_StatusByte_ClntTempTooHigh.Value
              IN_VeDMAB_y_StatusByte_CommBusOff_Value: accessed-variable=VeDMAB_y_StatusByte_CommBusOff.Value
              IN_VeDMAB_y_StatusByte_CommBus_B_Off_Value: accessed-variable=VeDMAB_y_StatusByte_CommBus_B_Off.Value
              IN_VeDMAB_y_StatusByte_DM_B_I_PwrSplyCkt_Value: accessed-variable=VeDMAB_y_StatusByte_DM_B_I_PwrSplyCkt.Value
              IN_VeDMAB_y_StatusByte_FD_CAN11_CommBusOff_Value: accessed-variable=VeDMAB_y_StatusByte_FD_CAN11_CommBusOff.Value
              IN_VeDMAB_y_StatusByte_FD_CAN11_CommBusPerf_Value: accessed-variable=VeDMAB_y_StatusByte_FD_CAN11_CommBusPerf.Value
              IN_VeDMAB_y_StatusByte_FD_CAN14_CommBusOff_Value: accessed-variable=VeDMAB_y_StatusByte_FD_CAN14_CommBusOff.Value
              IN_VeDMAB_y_StatusByte_FD_CAN14_CommBusPerf_Value: accessed-variable=VeDMAB_y_StatusByte_FD_CAN14_CommBusPerf.Value
              IN_VeDMAB_y_StatusByte_FD_CAN3_CommBusOff_Value: accessed-variable=VeDMAB_y_StatusByte_FD_CAN3_CommBusOff.Value
              IN_VeDMAB_y_StatusByte_FD_CAN3_CommBusPerf_Value: accessed-variable=VeDMAB_y_StatusByte_FD_CAN3_CommBusPerf.Value
              IN_VeDMAB_y_StatusByte_FD_CAN5_CommBusOff_Value: accessed-variable=VeDMAB_y_StatusByte_FD_CAN5_CommBusOff.Value
              IN_VeDMAB_y_StatusByte_FD_CAN5_CommBusPerf_Value: accessed-variable=VeDMAB_y_StatusByte_FD_CAN5_CommBusPerf.Value
              IN_VeDMAB_y_StatusByte_Fault_Value: accessed-variable=VeDMAB_y_StatusByte_Fault.Value
              IN_VeDMAB_y_StatusByte_HiSpdCANCommBus_Value: accessed-variable=VeDMAB_y_StatusByte_HiSpdCANCommBus.Value
              IN_VeDMAB_y_StatusByte_HiSpdCANCommBusPerf_Value: accessed-variable=VeDMAB_y_StatusByte_HiSpdCANCommBusPerf.Value
              IN_VeDMAB_y_StatusByte_HybBatPosConConCirPer_Value: accessed-variable=VeDMAB_y_StatusByte_HybBatPosConConCirPer.Value
              IN_VeDMAB_y_StatusByte_HybSysPerf1_Value: accessed-variable=VeDMAB_y_StatusByte_HybSysPerf1.Value
              IN_VeDMAB_y_StatusByte_HybSysPerf2_Value: accessed-variable=VeDMAB_y_StatusByte_HybSysPerf2.Value
              IN_VeDMAB_y_StatusByte_HybSysPerf5_Value: accessed-variable=VeDMAB_y_StatusByte_HybSysPerf5.Value
              IN_VeDMAB_y_StatusByte_HybridGenPerf_Slip_Value: accessed-variable=VeDMAB_y_StatusByte_HybridGenPerf_Slip.Value
              IN_VeDMAB_y_StatusByte_InvData_ABS_Value: accessed-variable=VeDMAB_y_StatusByte_InvData_ABS.Value
              IN_VeDMAB_y_StatusByte_InvData_ABSCM_A_Value: accessed-variable=VeDMAB_y_StatusByte_InvData_ABSCM_A.Value
              IN_VeDMAB_y_StatusByte_InvData_ABS_BusB_Value: accessed-variable=VeDMAB_y_StatusByte_InvData_ABS_BusB.Value
              IN_VeDMAB_y_StatusByte_InvData_APM_Value: accessed-variable=VeDMAB_y_StatusByte_InvData_APM.Value
              IN_VeDMAB_y_StatusByte_InvData_BCM_Value: accessed-variable=VeDMAB_y_StatusByte_InvData_BCM.Value
              IN_VeDMAB_y_StatusByte_InvData_BCS_Value: accessed-variable=VeDMAB_y_StatusByte_InvData_BCS.Value
              IN_VeDMAB_y_StatusByte_InvData_BECM_Value: accessed-variable=VeDMAB_y_StatusByte_InvData_BECM.Value
              IN_VeDMAB_y_StatusByte_InvData_BECM_CANC11_Value: accessed-variable=VeDMAB_y_StatusByte_InvData_BECM_CANC11.Value
              IN_VeDMAB_y_StatusByte_InvData_CADM_Value: accessed-variable=VeDMAB_y_StatusByte_InvData_CADM.Value
              IN_VeDMAB_y_StatusByte_InvData_CANC2_BCM_Value: accessed-variable=VeDMAB_y_StatusByte_InvData_CANC2_BCM.Value
              IN_VeDMAB_y_StatusByte_InvData_DMCM_A_Value: accessed-variable=VeDMAB_y_StatusByte_InvData_DMCM_A.Value
              IN_VeDMAB_y_StatusByte_InvData_DMCM_A_CANC11_Value: accessed-variable=VeDMAB_y_StatusByte_InvData_DMCM_A_CANC11.Value
              IN_VeDMAB_y_StatusByte_InvData_DMCM_B_Value: accessed-variable=VeDMAB_y_StatusByte_InvData_DMCM_B.Value
              IN_VeDMAB_y_StatusByte_InvData_ECM_Value: accessed-variable=VeDMAB_y_StatusByte_InvData_ECM.Value
              IN_VeDMAB_y_StatusByte_InvData_ECM_BusB_Value: accessed-variable=VeDMAB_y_StatusByte_InvData_ECM_BusB.Value
              IN_VeDMAB_y_StatusByte_InvData_ESM_Value: accessed-variable=VeDMAB_y_StatusByte_InvData_ESM.Value
              IN_VeDMAB_y_StatusByte_InvData_ESM_BusB_Value: accessed-variable=VeDMAB_y_StatusByte_InvData_ESM_BusB.Value
              IN_VeDMAB_y_StatusByte_InvData_GenrA_CM_Value: accessed-variable=VeDMAB_y_StatusByte_InvData_GenrA_CM.Value
              IN_VeDMAB_y_StatusByte_InvData_HapticCM_Value: accessed-variable=VeDMAB_y_StatusByte_InvData_HapticCM.Value
              IN_VeDMAB_y_StatusByte_InvData_IDCM_Value: accessed-variable=VeDMAB_y_StatusByte_InvData_IDCM.Value
              IN_VeDMAB_y_StatusByte_InvData_MCPA_CANC11_Value: accessed-variable=VeDMAB_y_StatusByte_InvData_MCPA_CANC11.Value
              IN_VeDMAB_y_StatusByte_InvData_MCPB_CANC11_Value: accessed-variable=VeDMAB_y_StatusByte_InvData_MCPB_CANC11.Value
              IN_VeDMAB_y_StatusByte_InvData_RHSC2_Value: accessed-variable=VeDMAB_y_StatusByte_InvData_RHSC2.Value
              IN_VeDMAB_y_StatusByte_InvData_SGCM_Value: accessed-variable=VeDMAB_y_StatusByte_InvData_SGCM.Value
              IN_VeDMAB_y_StatusByte_InvData_TCM_Value: accessed-variable=VeDMAB_y_StatusByte_InvData_TCM.Value
              IN_VeDMAB_y_StatusByte_InvData_TCM_BusB_Value: accessed-variable=VeDMAB_y_StatusByte_InvData_TCM_BusB.Value
              IN_VeDMAB_y_StatusByte_LF_WHL_HubDisConActCntrl_Value: accessed-variable=VeDMAB_y_StatusByte_LF_WHL_HubDisConActCntrl.Value
              IN_VeDMAB_y_StatusByte_LF_WHL_HubDisConActPosSnsr_Value: accessed-variable=VeDMAB_y_StatusByte_LF_WHL_HubDisConActPosSnsr.Value
              IN_VeDMAB_y_StatusByte_LF_WHL_HubDisConActPosSnsrCktPerf_Value: accessed-variable=VeDMAB_y_StatusByte_LF_WHL_HubDisConActPosSnsrCktPerf.Value
              IN_VeDMAB_y_StatusByte_LIN{1..3}_BusOff_Value: accessed-variable=VeDMAB_y_StatusByte_LIN{1..3}_BusOff.Value
              IN_VeDMAB_y_StatusByte_LoC_MCPA_CANC11_Value: accessed-variable=VeDMAB_y_StatusByte_LoC_MCPA_CANC11.Value
              IN_VeDMAB_y_StatusByte_LoC_MCPB_CANC11_Value: accessed-variable=VeDMAB_y_StatusByte_LoC_MCPB_CANC11.Value
              IN_VeDMAB_y_StatusByte_LosComWitAntBraSysABSConModB_Value: accessed-variable=VeDMAB_y_StatusByte_LosComWitAntBraSysABSConModB.Value
              IN_VeDMAB_y_StatusByte_LosCommBECM_A_Value: accessed-variable=VeDMAB_y_StatusByte_LosCommBECM_A.Value
              IN_VeDMAB_y_StatusByte_LosCommBECM_A_CANC11_Value: accessed-variable=VeDMAB_y_StatusByte_LosCommBECM_A_CANC11.Value
              IN_VeDMAB_y_StatusByte_LosComm_CADM_Value: accessed-variable=VeDMAB_y_StatusByte_LosComm_CADM.Value
              IN_VeDMAB_y_StatusByte_LostCommABSCM_Value: accessed-variable=VeDMAB_y_StatusByte_LostCommABSCM.Value
              IN_VeDMAB_y_StatusByte_LostCommABSCM_A_Value: accessed-variable=VeDMAB_y_StatusByte_LostCommABSCM_A.Value
              IN_VeDMAB_y_StatusByte_LostCommABS_BusB_Value: accessed-variable=VeDMAB_y_StatusByte_LostCommABS_BusB.Value
              IN_VeDMAB_y_StatusByte_LostCommBCM_Value: accessed-variable=VeDMAB_y_StatusByte_LostCommBCM.Value
              IN_VeDMAB_y_StatusByte_LostCommDCDC_Value: accessed-variable=VeDMAB_y_StatusByte_LostCommDCDC.Value
              IN_VeDMAB_y_StatusByte_LostCommDMCM_2_Value: accessed-variable=VeDMAB_y_StatusByte_LostCommDMCM_2.Value
              IN_VeDMAB_y_StatusByte_LostCommECM_A_BusB_Value: accessed-variable=VeDMAB_y_StatusByte_LostCommECM_A_BusB.Value
              IN_VeDMAB_y_StatusByte_LostCommECM_PCM_A_Value: accessed-variable=VeDMAB_y_StatusByte_LostCommECM_PCM_A.Value
              IN_VeDMAB_y_StatusByte_LostCommESM_BusB_Value: accessed-variable=VeDMAB_y_StatusByte_LostCommESM_BusB.Value
              IN_VeDMAB_y_StatusByte_LostCommHapticCM_Value: accessed-variable=VeDMAB_y_StatusByte_LostCommHapticCM.Value
              IN_VeDMAB_y_StatusByte_LostCommIDCM_Value: accessed-variable=VeDMAB_y_StatusByte_LostCommIDCM.Value
              IN_VeDMAB_y_StatusByte_LostCommIPC_Value: accessed-variable=VeDMAB_y_StatusByte_LostCommIPC.Value
              IN_VeDMAB_y_StatusByte_LostCommISM_Value: accessed-variable=VeDMAB_y_StatusByte_LostCommISM.Value
              IN_VeDMAB_y_StatusByte_LostCommMtrElectCoolPmpA_Value: accessed-variable=VeDMAB_y_StatusByte_LostCommMtrElectCoolPmpA.Value
              IN_VeDMAB_y_StatusByte_LostCommMtrElectCoolPmpB_Value: accessed-variable=VeDMAB_y_StatusByte_LostCommMtrElectCoolPmpB.Value
              IN_VeDMAB_y_StatusByte_LostCommPwrtrn_OilPmp1_Value: accessed-variable=VeDMAB_y_StatusByte_LostCommPwrtrn_OilPmp1.Value
              IN_VeDMAB_y_StatusByte_LostCommPwrtrn_OilPmp2_Value: accessed-variable=VeDMAB_y_StatusByte_LostCommPwrtrn_OilPmp2.Value
              IN_VeDMAB_y_StatusByte_LostCommRHSC2_Value: accessed-variable=VeDMAB_y_StatusByte_LostCommRHSC2.Value
              IN_VeDMAB_y_StatusByte_LostCommSGCM_Value: accessed-variable=VeDMAB_y_StatusByte_LostCommSGCM.Value
              IN_VeDMAB_y_StatusByte_LostCommTrans_Value: accessed-variable=VeDMAB_y_StatusByte_LostCommTrans.Value
              IN_VeDMAB_y_StatusByte_LostCommTrans_EPT_Value: accessed-variable=VeDMAB_y_StatusByte_LostCommTrans_EPT.Value
              IN_VeDMAB_y_StatusByte_LostComm_DMCM_A_Value: accessed-variable=VeDMAB_y_StatusByte_LostComm_DMCM_A.Value
              IN_VeDMAB_y_StatusByte_LostComm_DMCM_A_CANC11_Value: accessed-variable=VeDMAB_y_StatusByte_LostComm_DMCM_A_CANC11.Value
              IN_VeDMAB_y_StatusByte_LostComm_GenrA_CM_Value: accessed-variable=VeDMAB_y_StatusByte_LostComm_GenrA_CM.Value
              IN_VeDMAB_y_StatusByte_MtrElect_CoolPumAOvrSpd_Value: accessed-variable=VeDMAB_y_StatusByte_MtrElect_CoolPumAOvrSpd.Value
              IN_VeDMAB_y_StatusByte_PwrtrnOilPmp1OvrSpd_Value: accessed-variable=VeDMAB_y_StatusByte_PwrtrnOilPmp1OvrSpd.Value
              IN_VeDMAB_y_StatusByte_PwrtrnOilPmp2OvrSpd_Value: accessed-variable=VeDMAB_y_StatusByte_PwrtrnOilPmp2OvrSpd.Value
              IN_VeDMAB_y_StatusByte_RF_WHL_HubDisConActCntrl_Value: accessed-variable=VeDMAB_y_StatusByte_RF_WHL_HubDisConActCntrl.Value
              IN_VeDMAB_y_StatusByte_RF_WHL_HubDisConActPosSnsr_Value: accessed-variable=VeDMAB_y_StatusByte_RF_WHL_HubDisConActPosSnsr.Value
              IN_VeDMAB_y_StatusByte_RF_WHL_HubDisConActPosSnsrCktPerf_Value: accessed-variable=VeDMAB_y_StatusByte_RF_WHL_HubDisConActPosSnsrCktPerf.Value
              IN_VeDMAB_y_StatusByte_SPI_CommFlt_Value: accessed-variable=VeDMAB_y_StatusByte_SPI_CommFlt.Value
              IN_VeDMAB_y_StatusByte_StarterGenMechPerf_Slip_Value: accessed-variable=VeDMAB_y_StatusByte_StarterGenMechPerf_Slip.Value
              IN_VeDMAB_y_StatusByte_VehSpd_OSS_Corr_Value: accessed-variable=VeDMAB_y_StatusByte_VehSpd_OSS_Corr.Value
              IN_VeDMDR_e_TurtleMdSts_Value: accessed-variable=VeDMDR_e_TurtleMdSts.Value
              IN_VeDMIR_e_DriveStyleSts_Value: accessed-variable=VeDMIR_e_DriveStyleSts.Value
              IN_VeDTRR_b_AxleTrqReqPrdtFA_Value: accessed-variable=VeDTRR_b_AxleTrqReqPrdtFA.Value
              IN_VeDTRR_b_DrvrIntndedAxleTrqRawFA_Value: accessed-variable=VeDTRR_b_DrvrIntndedAxleTrqRawFA.Value
              IN_VeDTRR_b_OPDInhibit_HMI_Value: accessed-variable=VeDTRR_b_OPDInhibit_HMI.Value
              IN_VeENGR_b_ECM_Feedback_HCP_Value: accessed-variable=VeENGR_b_ECM_Feedback_HCP.Value
              IN_VeENGR_b_EngOffRecom_Value: accessed-variable=VeENGR_b_EngOffRecom.Value
              IN_VeENGR_b_EngSysLowFuel_Value: accessed-variable=VeENGR_b_EngSysLowFuel.Value
              IN_VeENGR_b_EngTrq_Enbl_Rq_TCM_Value: accessed-variable=VeENGR_b_EngTrq_Enbl_Rq_TCM.Value
              IN_VeENGR_b_EngineStallDetected_Value: accessed-variable=VeENGR_b_EngineStallDetected.Value
              IN_VeENGR_b_LV12PwrFreeRq_Value: accessed-variable=VeENGR_b_LV12PwrFreeRq.Value
              IN_VeENGR_b_ZylAbs_Value: accessed-variable=VeENGR_b_ZylAbs.Value
              IN_VeENGR_e_ComFailECM_C1CAN_Value: accessed-variable=VeENGR_e_ComFailECM_C1CAN.Value
              IN_VeENGR_e_ComFailECM_ePtCAN_Value: accessed-variable=VeENGR_e_ComFailECM_ePtCAN.Value
              IN_VeENGR_e_ECMReqRemStop_Value: accessed-variable=VeENGR_e_ECMReqRemStop.Value
              IN_VeENGR_i_ECM_LHOM_Trans_Value: accessed-variable=VeENGR_i_ECM_LHOM_Trans.Value
              IN_VeESPR_b_EngNegSpdFltDtct_Value: accessed-variable=VeESPR_b_EngNegSpdFltDtct.Value
              IN_VeESPR_b_EngOvrSpdFltDtct_Value: accessed-variable=VeESPR_b_EngOvrSpdFltDtct.Value
              IN_VeESPR_e_EngineSpeedStatus_Value: accessed-variable=VeESPR_e_EngineSpeedStatus.Value
              IN_VeESSR_b_AStrtFailed_Value: accessed-variable=VeESSR_b_AStrtFailed.Value
              IN_VeESSR_b_AStrtReattmptAllowed_Value: accessed-variable=VeESSR_b_AStrtReattmptAllowed.Value
              IN_VeESSR_e_EngStartStopSt_Value: accessed-variable=VeESSR_e_EngStartStopSt.Value
              IN_VeESSR_e_EngStrtStpMd_Value: accessed-variable=VeESSR_e_EngStrtStpMd.Value
              IN_VeESSR_g_StrtStpFailPhase_Value: accessed-variable=VeESSR_g_StrtStpFailPhase.Value
              IN_VeETQR_M_EngTrqActual_Value: accessed-variable=VeETQR_M_EngTrqActual.Value
              IN_VeETQR_b_EngTrqActual_FA_Value: accessed-variable=VeETQR_b_EngTrqActual_FA.Value
              IN_VeGENR_U_IBS_BattVoltOut_Value: accessed-variable=VeGENR_U_IBS_BattVoltOut.Value
              IN_VeGENR_b_LowVoltSysFld_Value: accessed-variable=VeGENR_b_LowVoltSysFld.Value
              IN_VeGSMR_b_PpawlInsrtMntrFailed_Value: accessed-variable=VeGSMR_b_PpawlInsrtMntrFailed.Value
              IN_VeHCCR_V_UpperSump_Vol_Value: accessed-variable=VeHCCR_V_UpperSump_Vol.Value
              IN_VeHCCR_e_SCA1_St_Value: accessed-variable=VeHCCR_e_SCA1_St.Value
              IN_VeHCCR_e_SCA2_St_Value: accessed-variable=VeHCCR_e_SCA2_St.Value
              IN_VeHMIR_b_DriveReady_Value: accessed-variable=VeHMIR_b_DriveReady.Value
              IN_VeHPMR_b_MtrSystemActive_Value: accessed-variable=VeHPMR_b_MtrSystemActive.Value
              IN_VeHPMR_b_PropSysActv_Value: accessed-variable=VeHPMR_b_PropSysActv.Value
              IN_VeHPMR_e_PropSysMode_Value: accessed-variable=VeHPMR_e_PropSysMode.Value
              IN_VeHPMR_t_PropSysActvTmr_Value: accessed-variable=VeHPMR_t_PropSysActvTmr.Value
              IN_VeHSCR_n_Max_MtrA_Spd_Value: accessed-variable=VeHSCR_n_Max_MtrA_Spd.Value
              IN_VeHSCR_n_Max_MtrB_Spd_Value: accessed-variable=VeHSCR_n_Max_MtrB_Spd.Value
              IN_VeHSER_b_GRMActive_Value: accessed-variable=VeHSER_b_GRMActive.Value
              IN_VeHSER_e_RngEqnSel_Value: accessed-variable=VeHSER_e_RngEqnSel.Value
              IN_VeHSER_e_RngSt_Value: accessed-variable=VeHSER_e_RngSt.Value
              IN_VeHTRR_b_Htr3Cntctr_StckClsdOvrTmp_Flg_Value: accessed-variable=VeHTRR_b_Htr3Cntctr_StckClsdOvrTmp_Flg.Value
              IN_VeIDCR_e_APM_FailureType_Value: accessed-variable=VeIDCR_e_APM_FailureType.Value
              IN_VeIMPR_b_HighVoltageRapidShtdwnCmnd_Value: accessed-variable=VeIMPR_b_HighVoltageRapidShtdwnCmnd.Value
              IN_VeINVR_T_MtrA_InvrtrTemp_Value: accessed-variable=VeINVR_T_MtrA_InvrtrTemp.Value
              IN_VeINVR_T_MtrA_Temp_Value: accessed-variable=VeINVR_T_MtrA_Temp.Value
              IN_VeINVR_T_MtrB_InvrtrTemp_Value: accessed-variable=VeINVR_T_MtrB_InvrtrTemp.Value
              IN_VeINVR_T_MtrB_Temp_Value: accessed-variable=VeINVR_T_MtrB_Temp.Value
              IN_VeINVR_b_BstCnvtrFailStsFA_Value: accessed-variable=VeINVR_b_BstCnvtrFailStsFA.Value
              IN_VeINVR_b_DMPI_TempStopFlag_Value: accessed-variable=VeINVR_b_DMPI_TempStopFlag.Value
              IN_VeINVR_b_MCPA_CommFailFA_Value: accessed-variable=VeINVR_b_MCPA_CommFailFA.Value
              IN_VeINVR_b_MCPB_CommFailFA_Value: accessed-variable=VeINVR_b_MCPB_CommFailFA.Value
              IN_VeINVR_b_MtrAFlt_HV_CntctrOpnRq_Value: accessed-variable=VeINVR_b_MtrAFlt_HV_CntctrOpnRq.Value
              IN_VeINVR_b_MtrA_DC_CrntFA_Value: accessed-variable=VeINVR_b_MtrA_DC_CrntFA.Value
              IN_VeINVR_b_MtrA_DC_VoltFA_Value: accessed-variable=VeINVR_b_MtrA_DC_VoltFA.Value
              IN_VeINVR_b_MtrA_InvrtrTempFA_Value: accessed-variable=VeINVR_b_MtrA_InvrtrTempFA.Value
              IN_VeINVR_b_MtrA_TempFA_Value: accessed-variable=VeINVR_b_MtrA_TempFA.Value
              IN_VeINVR_b_MtrBFlt_HV_CntctrOpnRq_Value: accessed-variable=VeINVR_b_MtrBFlt_HV_CntctrOpnRq.Value
              IN_VeINVR_b_MtrBFlt_HV_CntctrOpnRq_FA_Value: accessed-variable=VeINVR_b_MtrBFlt_HV_CntctrOpnRq_FA.Value
              IN_VeINVR_b_MtrB_DC_CrntFA_Value: accessed-variable=VeINVR_b_MtrB_DC_CrntFA.Value
              IN_VeINVR_b_MtrB_DC_VoltFA_Value: accessed-variable=VeINVR_b_MtrB_DC_VoltFA.Value
              IN_VeINVR_b_MtrB_InvrtrTempFA_Value: accessed-variable=VeINVR_b_MtrB_InvrtrTempFA.Value
              IN_VeINVR_b_MtrB_TempFA_Value: accessed-variable=VeINVR_b_MtrB_TempFA.Value
              IN_VeINVR_b_MtrCFlt_HV_CntctrOpnRq_Value: accessed-variable=VeINVR_b_MtrCFlt_HV_CntctrOpnRq.Value
              IN_VeINVR_b_P1f_Dgrd_AltMd_Value: accessed-variable=VeINVR_b_P1f_Dgrd_AltMd.Value
              IN_VeINVR_e_BstCnvtrFailSts_Value: accessed-variable=VeINVR_e_BstCnvtrFailSts.Value
              IN_VeINVR_e_MCPA_CommFail_Value: accessed-variable=VeINVR_e_MCPA_CommFail.Value
              IN_VeINVR_e_MCPB_CommFail_Value: accessed-variable=VeINVR_e_MCPB_CommFail.Value
              IN_VeINVR_e_MtrA_InvrtrSt_Value: accessed-variable=VeINVR_e_MtrA_InvrtrSt.Value
              IN_VeINVR_e_MtrB_InvrtrSt_Value: accessed-variable=VeINVR_e_MtrB_InvrtrSt.Value
              IN_VeINVR_e_MtrC_InvrtrSt_Value: accessed-variable=VeINVR_e_MtrC_InvrtrSt.Value
              IN_VeMMMR_b_MtrMdVldtnFlt_Value: accessed-variable=VeMMMR_b_MtrMdVldtnFlt.Value
              IN_VeMSPR_b_MtrA_SpdFARaw_Value: accessed-variable=VeMSPR_b_MtrA_SpdFARaw.Value
              IN_VeMSPR_b_MtrB_SpdFARaw_Value: accessed-variable=VeMSPR_b_MtrB_SpdFARaw.Value
              IN_VeMSPR_n_MtrB_Spd_Value: accessed-variable=VeMSPR_n_MtrB_Spd.Value
              IN_VeMTIR_b_MtrA_TorqAchievedFA_Value: accessed-variable=VeMTIR_b_MtrA_TorqAchievedFA.Value
              IN_VeMTIR_b_MtrB_TorqAchievedFA_Value: accessed-variable=VeMTIR_b_MtrB_TorqAchievedFA.Value
              IN_VeOBCR_e_ChargingLevel_Value: accessed-variable=VeOBCR_e_ChargingLevel.Value
              IN_VeOBCR_e_ChargingSystemSts_Value: accessed-variable=VeOBCR_e_ChargingSystemSts.Value
              IN_VeOBCR_e_ChrgSysShtDwnFlt_Value: accessed-variable=VeOBCR_e_ChrgSysShtDwnFlt.Value
              IN_VeOHSR_e_RngDsrd_Value: accessed-variable=VeOHSR_e_RngDsrd.Value
              IN_VeOSMR_n_TransMinEngSpd_Value: accessed-variable=VeOSMR_n_TransMinEngSpd.Value
              IN_VePLTR_b_InFieldMode_Value: accessed-variable=VePLTR_b_InFieldMode.Value
              IN_VePLTR_b_RmtVehStartReq_Value: accessed-variable=VePLTR_b_RmtVehStartReq.Value
              IN_VePMDR_b_SysVoltHighFA_Value: accessed-variable=VePMDR_b_SysVoltHighFA.Value
              IN_VePMDR_b_SysVoltLowFA_Value: accessed-variable=VePMDR_b_SysVoltLowFA.Value
              IN_VePMDR_b_SysVoltLowFA_BF{1..3}_Value: accessed-variable=VePMDR_b_SysVoltLowFA_BF{1..3}.Value
              IN_VePMDR_b_SysVoltLowFA_HB_Value: accessed-variable=VePMDR_b_SysVoltLowFA_HB.Value
              IN_VePMDR_e_KeyStatus_Value: accessed-variable=VePMDR_e_KeyStatus.Value
              IN_VePMDR_e_PMM_PowerMode_Value: accessed-variable=VePMDR_e_PMM_PowerMode.Value
              IN_VePMDR_t_RunCrankActive_Value: accessed-variable=VePMDR_t_RunCrankActive.Value
              IN_VePMIR_e_LTPsvPumpDryRun_Value: accessed-variable=VePMIR_e_LTPsvPumpDryRun.Value
              IN_VePWDR_b_BattOverTempFltDtct_Value: accessed-variable=VePWDR_b_BattOverTempFltDtct.Value
              IN_VePWDR_b_BattOverTempWarning_Value: accessed-variable=VePWDR_b_BattOverTempWarning.Value
              IN_VePWDR_b_HVOverVoltFltDtct_Value: accessed-variable=VePWDR_b_HVOverVoltFltDtct.Value
              IN_VePWDR_b_HVUnderVoltFltDtct_Value: accessed-variable=VePWDR_b_HVUnderVoltFltDtct.Value
              IN_VePWDR_b_SOCHighFltDtct_Value: accessed-variable=VePWDR_b_SOCHighFltDtct.Value
              IN_VePWDR_b_SOCLowFltDtct_Value: accessed-variable=VePWDR_b_SOCLowFltDtct.Value
              IN_VePWDR_e_HVOverVoltFailure_Value: accessed-variable=VePWDR_e_HVOverVoltFailure.Value
              IN_VeSSDR_b_DrvAllwd_Value: accessed-variable=VeSSDR_b_DrvAllwd.Value
              IN_VeSTMR_b_RngStValidationFlt_Value: accessed-variable=VeSTMR_b_RngStValidationFlt.Value
              IN_VeSTMR_b_TransOutTrqCmdFlt_Value: accessed-variable=VeSTMR_b_TransOutTrqCmdFlt.Value
              IN_VeSTRR_b_BumpStrtEngOn_Value: accessed-variable=VeSTRR_b_BumpStrtEngOn.Value
              IN_VeSTRR_b_BumpStrtInhbt_Value: accessed-variable=VeSTRR_b_BumpStrtInhbt.Value
              IN_VeSTRR_b_ImmedStop_Value: accessed-variable=VeSTRR_b_ImmedStop.Value
              IN_VeSTRR_e_HybStrtrSt_Value: accessed-variable=VeSTRR_e_HybStrtrSt.Value
              IN_VeTAPR_b_TransAuxPump_NotFlty_Value: accessed-variable=VeTAPR_b_TransAuxPump_NotFlty.Value
              IN_VeTFTR_T_TransOilTemp_Value: accessed-variable=VeTFTR_T_TransOilTemp.Value
              IN_VeTFTR_b_TransOilTempFA_Value: accessed-variable=VeTFTR_b_TransOilTempFA.Value
              IN_VeTHMR_b_ThermalHybAltMode_Rq_Value: accessed-variable=VeTHMR_b_ThermalHybAltMode_Rq.Value
              IN_VeTHMR_e_PPCTIS_OT_Value: accessed-variable=VeTHMR_e_PPCTIS_OT.Value
              IN_VeTHMR_e_ThrmSysShtDwnFlt_Value: accessed-variable=VeTHMR_e_ThrmSysShtDwnFlt.Value
              IN_VeTIDR_b_EngTrqHVBattHiFA_Value: accessed-variable=VeTIDR_b_EngTrqHVBattHiFA.Value
              IN_VeTIDR_b_EngTrqHVBattLoFA_Value: accessed-variable=VeTIDR_b_EngTrqHVBattLoFA.Value
              IN_VeTINR_b_Inhibit_Gear{1..4}_Value: accessed-variable=VeTINR_b_Inhibit_Gear{1..4}.Value
              IN_VeTINR_b_Inhibit_Mode1_Value: accessed-variable=VeTINR_b_Inhibit_Mode1.Value
              IN_VeTINR_b_Inhibit_Mode2_Value: accessed-variable=VeTINR_b_Inhibit_Mode2.Value
              IN_VeTINR_d_TCMFailures_Value: accessed-variable=VeTINR_d_TCMFailures.Value
              IN_VeTINR_d_TCMLimphomeFaults_Value: accessed-variable=VeTINR_d_TCMLimphomeFaults.Value
              IN_VeTINR_e_ComFailTCM_C1CAN_Value: accessed-variable=VeTINR_e_ComFailTCM_C1CAN.Value
              IN_VeTINR_e_ComFailTCM_ePtCAN_Value: accessed-variable=VeTINR_e_ComFailTCM_ePtCAN.Value
              IN_VeTINR_e_Synchro1Sts_Value: accessed-variable=VeTINR_e_Synchro1Sts.Value
              IN_VeTINR_e_Synchro2Sts_Value: accessed-variable=VeTINR_e_Synchro2Sts.Value
              IN_VeTINR_e_TransLimpRequest_Value: accessed-variable=VeTINR_e_TransLimpRequest.Value
              IN_VeTISR_b_InputSpdRatlFlt_FltDtct_Value: accessed-variable=VeTISR_b_InputSpdRatlFlt_FltDtct.Value
              IN_VeTISR_b_InputSpeedFA_Value: accessed-variable=VeTISR_b_InputSpeedFA.Value
              IN_VeTISR_b_TransInAng720EstErr_Value: accessed-variable=VeTISR_b_TransInAng720EstErr.Value
              IN_VeTISR_n_InputSpeed_Value: accessed-variable=VeTISR_n_InputSpeed.Value
              IN_VeTITR_M_SnsdEng_Flt_Value: accessed-variable=VeTITR_M_SnsdEng_Flt.Value
              IN_VeTMIR_T_PsvPmpClnt_TmpIn_Value: accessed-variable=VeTMIR_T_PsvPmpClnt_TmpIn.Value
              IN_VeTRGR_b_DisableDrvAllwd_Value: accessed-variable=VeTRGR_b_DisableDrvAllwd.Value
              IN_VeTRGR_e_EPB_Hold_Req_Value: accessed-variable=VeTRGR_e_EPB_Hold_Req.Value
              IN_VeTRGR_e_VldtdTransRngSt_Value: accessed-variable=VeTRGR_e_VldtdTransRngSt.Value
              IN_VeTRMR_b_PRNDL_MontrFlt_Value: accessed-variable=VeTRMR_b_PRNDL_MontrFlt.Value
              IN_VeTRNR_e_ActualGear_Value: accessed-variable=VeTRNR_e_ActualGear.Value
              IN_VeTRNR_e_C1Stat_Value: accessed-variable=VeTRNR_e_C1Stat.Value
              IN_VeTRNR_e_C2Stat_Value: accessed-variable=VeTRNR_e_C2Stat.Value
              IN_VeTRNR_e_TCMActualEvenGear_Value: accessed-variable=VeTRNR_e_TCMActualEvenGear.Value
              IN_VeTRNR_e_TargetGear_Value: accessed-variable=VeTRNR_e_TargetGear.Value
              IN_VeTTIR_b_TransTrqReqFst_Pass_Value: accessed-variable=VeTTIR_b_TransTrqReqFst_Pass.Value
              IN_VeVSDR_e_PrimNoSrc_Value: accessed-variable=VeVSDR_e_PrimNoSrc.Value
              IN_VeVSDR_n_PrimNoSgndFltrd_Value: accessed-variable=VeVSDR_n_PrimNoSgndFltrd.Value
          data-send-points:
            99 x access:
              OUT_VeSRAR_n_HCPMaxEngRPM_Value: accessed-variable=VeSRAR_n_HCPMaxEngRPM.Value
              OUT_VeSRAR_b_CAN_HybFeedback_ECM_Value: accessed-variable=VeSRAR_b_CAN_HybFeedback_ECM.Value
              OUT_VeSRAR_b_Inhibit_NeutralCmnd_Value: accessed-variable=VeSRAR_b_Inhibit_NeutralCmnd.Value
              OUT_VeSRAR_b_Inhibit_Mode1Cmnd_Value: accessed-variable=VeSRAR_b_Inhibit_Mode1Cmnd.Value
              OUT_VeSRAR_b_Inhibit_Mode2Cmnd_Value: accessed-variable=VeSRAR_b_Inhibit_Mode2Cmnd.Value
              OUT_VeSRAR_b_Inhibit_Gear{1..4}Cmnd_Value: accessed-variable=VeSRAR_b_Inhibit_Gear{1..4}Cmnd.Value
              OUT_VeSRAR_b_RegenBrkInhb_Value: accessed-variable=VeSRAR_b_RegenBrkInhb.Value
              OUT_VeSRAR_b_HybPwrtrnRdcdPerfCmnd_Value: accessed-variable=VeSRAR_b_HybPwrtrnRdcdPerfCmnd.Value
              OUT_VeSRAR_b_ReducedPerfMode_Value: accessed-variable=VeSRAR_b_ReducedPerfMode.Value
              OUT_VeSRAR_b_ReducedPerfMode2_Value: accessed-variable=VeSRAR_b_ReducedPerfMode2.Value
              OUT_VeSRAR_b_CreepTorqMode_Value: accessed-variable=VeSRAR_b_CreepTorqMode.Value
              OUT_VeSRAR_b_limitInputTrq_Value: accessed-variable=VeSRAR_b_limitInputTrq.Value
              OUT_VeSRAR_b_FltShtDwnBPClsdCmnd_Value: accessed-variable=VeSRAR_b_FltShtDwnBPClsdCmnd.Value
              OUT_VeSRAR_b_FltShtDwnCmnd_Value: accessed-variable=VeSRAR_b_FltShtDwnCmnd.Value
              OUT_VeSRAR_e_EngStrtStpOvrrd_Value: accessed-variable=VeSRAR_e_EngStrtStpOvrrd.Value
              OUT_VeSRAR_b_LimTrans_Value: accessed-variable=VeSRAR_b_LimTrans.Value
              OUT_VeSRAR_b_EngStrtStpEngShtDwn_Value: accessed-variable=VeSRAR_b_EngStrtStpEngShtDwn.Value
              OUT_VeSRAR_b_EngStrtStpEngRun_Value: accessed-variable=VeSRAR_b_EngStrtStpEngRun.Value
              OUT_VeSRAR_b_FltShtDwnCmndRet_Value: accessed-variable=VeSRAR_b_FltShtDwnCmndRet.Value
              OUT_VeSRAR_b_RA_Actv_Value: accessed-variable=VeSRAR_b_RA_Actv.Value
              OUT_VeSRAR_b_TCMCommFltM1Only_Value: accessed-variable=VeSRAR_b_TCMCommFltM1Only.Value
              OUT_VeSRAR_b_TCMCommFltM2Only_Value: accessed-variable=VeSRAR_b_TCMCommFltM2Only.Value
              OUT_VeSRAR_b_Inhibit_GearsCmnd_Value: accessed-variable=VeSRAR_b_Inhibit_GearsCmnd.Value
              OUT_VeSRAR_y_RemedialActionHist_Value: accessed-variable=VeSRAR_y_RemedialActionHist.Value
              OUT_VeSRAR_b_HCP_Remedial_Stop_Value: accessed-variable=VeSRAR_b_HCP_Remedial_Stop.Value
              OUT_VeSRAR_b_DrvAllwd_Value: accessed-variable=VeSRAR_b_DrvAllwd.Value
              OUT_VeSRAR_b_NeutAllwd_Value: accessed-variable=VeSRAR_b_NeutAllwd.Value
              OUT_VeSRAR_k_ReasonStopCharging_Value: accessed-variable=VeSRAR_k_ReasonStopCharging.Value
              OUT_VeSRAR_e_EngStrtType_Value: accessed-variable=VeSRAR_e_EngStrtType.Value
              OUT_VeSRAR_b_OutOfFuelSOCShtDwn_Value: accessed-variable=VeSRAR_b_OutOfFuelSOCShtDwn.Value
              OUT_VeSRAR_b_HybFeedback_ECM_Value: accessed-variable=VeSRAR_b_HybFeedback_ECM.Value
              OUT_VeSRAR_scl_DisableAEMD_Value: accessed-variable=VeSRAR_scl_DisableAEMD.Value
              OUT_VeSRAR_b_DsblInvA_Value: accessed-variable=VeSRAR_b_DsblInvA.Value
              OUT_VeSRAR_b_DsblInvB_Value: accessed-variable=VeSRAR_b_DsblInvB.Value
              OUT_VeSRAR_b_OpnBattCntctr_Value: accessed-variable=VeSRAR_b_OpnBattCntctr.Value
              OUT_VeSRAR_e_EPB_Hold_Req_Value: accessed-variable=VeSRAR_e_EPB_Hold_Req.Value
              OUT_VeSRAR_b_EngShutDwn_EngOffKeyStrtinNeutralOnly_Value: accessed-variable=VeSRAR_b_EngShutDwn_EngOffKeyStrtinNeutralOnly.Value
              OUT_VeSRAR_b_FltShtDwnBPClsdCmnd_bfDly_Value: accessed-variable=VeSRAR_b_FltShtDwnBPClsdCmnd_bfDly.Value
              OUT_VeSRAR_b_FltShtDwnCmnd_bfDly_Value: accessed-variable=VeSRAR_b_FltShtDwnCmnd_bfDly.Value
              OUT_VeSRAR_b_DsblPSA_PlgIn_EngOn_Value: accessed-variable=VeSRAR_b_DsblPSA_PlgIn_EngOn.Value
              OUT_VeSRAR_b_EngStrtStpEngShtDwnIntm_Value: accessed-variable=VeSRAR_b_EngStrtStpEngShtDwnIntm.Value
              OUT_VeSRAR_b_TempEngShtDwnEnbl_Value: accessed-variable=VeSRAR_b_TempEngShtDwnEnbl.Value
              OUT_VeSRAR_b_SPIFlt_Value: accessed-variable=VeSRAR_b_SPIFlt.Value
              OUT_VeSRAR_b_SharedMemFlt_Value: accessed-variable=VeSRAR_b_SharedMemFlt.Value
              OUT_VeSRAR_b_StpCharging_Value: accessed-variable=VeSRAR_b_StpCharging.Value
              OUT_VeSRAR_b_VehShutoffSoon_Value: accessed-variable=VeSRAR_b_VehShutoffSoon.Value
              OUT_VeSRAR_b_Dsbl_MtrB_IdlSpd_Value: accessed-variable=VeSRAR_b_Dsbl_MtrB_IdlSpd.Value
              OUT_VeSRAR_b_Inhibit_DriveMode_Value: accessed-variable=VeSRAR_b_Inhibit_DriveMode.Value
              OUT_VeSRAR_b_Inhibit_AWD_TerrainMode_Value: accessed-variable=VeSRAR_b_Inhibit_AWD_TerrainMode.Value
              OUT_VeSRAR_b_DsblAECoasting_Value: accessed-variable=VeSRAR_b_DsblAECoasting.Value
              OUT_VeSRAR_b_LV12PwrFreeReq_PHEV_Value: accessed-variable=VeSRAR_b_LV12PwrFreeReq_PHEV.Value
              OUT_VeSRAR_b_TrqEnblReq_TCM_PHEV_Value: accessed-variable=VeSRAR_b_TrqEnblReq_TCM_PHEV.Value
              OUT_VeSRAR_i_LHOM_Trans_PHEV_Value: accessed-variable=VeSRAR_i_LHOM_Trans_PHEV.Value
              OUT_VeSRAR_b_DerateSumTrqMax_Value: accessed-variable=VeSRAR_b_DerateSumTrqMax.Value
              OUT_VeSRAR_b_Inhibit_RWD_TerrainMode_Value: accessed-variable=VeSRAR_b_Inhibit_RWD_TerrainMode.Value
              OUT_VeSRAR_b_HybAlternatorMd_Value: accessed-variable=VeSRAR_b_HybAlternatorMd.Value
              OUT_VeSRAR_b_InhibitGSI_Value: accessed-variable=VeSRAR_b_InhibitGSI.Value
              OUT_VeSRAR_e_LoCHCP_BPCM_ePT_Value: accessed-variable=VeSRAR_e_LoCHCP_BPCM_ePT.Value
              OUT_VeSRAR_e_LoCHCP_TCMECM_CANC_Value: accessed-variable=VeSRAR_e_LoCHCP_TCMECM_CANC.Value
              OUT_VeSRAR_e_LoCAHCP_BSM_CANC2_Value: accessed-variable=VeSRAR_e_LoCAHCP_BSM_CANC2.Value
              OUT_VeSRAR_e_LoCHCP_TCMECM_ePT_Value: accessed-variable=VeSRAR_e_LoCHCP_TCMECM_ePT.Value
              OUT_VeSRAR_e_LoCHCP_BSM_CANC_Value: accessed-variable=VeSRAR_e_LoCHCP_BSM_CANC.Value
              OUT_VeSRAR_b_InhibitCruise_Value: accessed-variable=VeSRAR_b_InhibitCruise.Value
              OUT_VeSRAR_b_ThmlLoadShdActv_Value: accessed-variable=VeSRAR_b_ThmlLoadShdActv.Value
              OUT_VeSRAR_b_OnePedalDriveDsbl_Value: accessed-variable=VeSRAR_b_OnePedalDriveDsbl.Value
              OUT_VeSRAR_b_Veh_Spd_Lmtd_Value: accessed-variable=VeSRAR_b_Veh_Spd_Lmtd.Value
              OUT_VeSRAR_b_PerfLmtd_StpSfly_Value: accessed-variable=VeSRAR_b_PerfLmtd_StpSfly.Value
              OUT_VeSRAR_b_InhibitActvSpdLmtr_Value: accessed-variable=VeSRAR_b_InhibitActvSpdLmtr.Value
              OUT_VeSRAR_b_Popup_Msg1_Value: accessed-variable=VeSRAR_b_Popup_Msg1.Value
              OUT_VeSRAR_b_Popup_Msg9_Value: accessed-variable=VeSRAR_b_Popup_Msg9.Value
              OUT_VeSRAR_b_Popup_Msg14_Value: accessed-variable=VeSRAR_b_Popup_Msg14.Value
              OUT_VeSRAR_b_Popup_Msg15_Value: accessed-variable=VeSRAR_b_Popup_Msg15.Value
              OUT_VeSRAR_b_MtrBZeroTrqActv_Value: accessed-variable=VeSRAR_b_MtrBZeroTrqActv.Value
              OUT_VeSRAR_b_K0AsyncCloseActv_Value: accessed-variable=VeSRAR_b_K0AsyncCloseActv.Value
              OUT_VeSRAR_b_InplantCreepModeRqst_Value: accessed-variable=VeSRAR_b_InplantCreepModeRqst.Value
              OUT_VeSRAR_b_Dsbl_SL_PID_Value: accessed-variable=VeSRAR_b_Dsbl_SL_PID.Value
              OUT_VeSRAR_b_MtrA_AlternatorMdAvbl_Value: accessed-variable=VeSRAR_b_MtrA_AlternatorMdAvbl.Value
              OUT_VeSRAR_g_RA_InputSet{1..8}_Value: accessed-variable=VeSRAR_g_RA_InputSet{1..8}.Value
              OUT_VeSRAR_b_Inhibit_eBoost_Value: accessed-variable=VeSRAR_b_Inhibit_eBoost.Value
              OUT_VeSRAR_b_MtrAZeroTrqActv_Value: accessed-variable=VeSRAR_b_MtrAZeroTrqActv.Value
              OUT_VeSRAR_b_MtrCZeroTrqActv_Value: accessed-variable=VeSRAR_b_MtrCZeroTrqActv.Value
              OUT_VeSRAR_b_DsblInvC_Value: accessed-variable=VeSRAR_b_DsblInvC.Value
              OUT_VeSRAR_b_HMI_LeaveIgnition_ON_Value: accessed-variable=VeSRAR_b_HMI_LeaveIgnition_ON.Value
              OUT_VeSRAR_b_Disable_RaceStart_Value: accessed-variable=VeSRAR_b_Disable_RaceStart.Value
              OUT_VeSRAR_b_Disable_PwrPanel_Value: accessed-variable=VeSRAR_b_Disable_PwrPanel.Value
              OUT_VeSRAR_b_InvrtrShortCntcrWeld_Value: accessed-variable=VeSRAR_b_InvrtrShortCntcrWeld.Value
              OUT_VeSRAR_b_Disable_TCaseSpeedSync_Value: accessed-variable=VeSRAR_b_Disable_TCaseSpeedSync.Value
              OUT_VeSRAR_b_BSMLoCBusOff_CANC_C2_Value: accessed-variable=VeSRAR_b_BSMLoCBusOff_CANC_C2.Value
              OUT_VeSRAR_g_RA_InputSet9_Value: accessed-variable=VeSRAR_g_RA_InputSet9.Value
          parameter access CALPRM_KeTSXR_r_P1f_KeTSXR_r_P1f: accessed-parameter=KeTSXR_r_P1f.KeTSXR_r_P1f
          read-local-variables:
            access RV_VeDCAB_b_CreepModeReq_DidWrite_out_IRV: accessed-variable=VeDCAB_b_CreepModeReq_DidWrite_out_IRV
            access RV_VeSRAR_n_HCPMaxEngRPM_write_IRV: accessed-variable=VeSRAR_n_HCPMaxEngRPM_write_IRV
        SRAR_PwrOff
          data-send-points:
            12 x access:
              OUT_NeSRAR_e_EngStrtType_DS_NeSRAR_e_EngStrtType_DS: accessed-variable=NeSRAR_e_EngStrtType_DS.NeSRAR_e_EngStrtType_DS
              OUT_NeSRAR_g_InputHist_{1..8}_DS_NeSRAR_g_InputHist_{1..8}_DS: accessed-variable=NeSRAR_g_InputHist_{1..8}_DS.NeSRAR_g_InputHist_{1..8}_DS
              OUT_NeSRAR_d_ReasonStopCharging_DS_NeSRAR_d_ReasonStopCharging_DS: accessed-variable=NeSRAR_d_ReasonStopCharging_DS.NeSRAR_d_ReasonStopCharging_DS
              OUT_NeSRAR_d_RemedialActionHist_DS_NeSRAR_d_RemedialActionHist_DS: accessed-variable=NeSRAR_d_RemedialActionHist_DS.NeSRAR_d_RemedialActionHist_DS
              OUT_NeSRAR_g_InputHist_9_DS_NeSRAR_g_InputHist_9_DS: accessed-variable=NeSRAR_g_InputHist_9_DS.NeSRAR_g_InputHist_9_DS
        DIDWrite_CreepModeReq
          data-receive-point-by-arguments:
            access IN_VeDCAB_b_CreepModeReq_DidWrite_Value: accessed-variable=VeDCAB_b_CreepModeReq_DidWrite.Value
          written-local-variables:
            access WV_VeDCAB_b_CreepModeReq_DidWrite_out_IRV: accessed-variable=VeDCAB_b_CreepModeReq_DidWrite_out_IRV
      4 x variation point proxy, all with category=CONDITION, condition-access=0:
        Variant_SRAR_{1..4}
